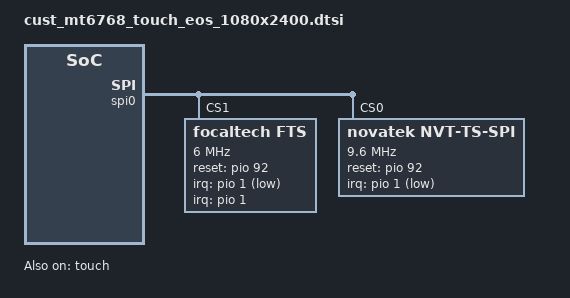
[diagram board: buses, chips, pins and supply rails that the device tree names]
/*
 * Copyright (c) 2019 MediaTek Inc.
 *
 * This program is free software; you can redistribute it and/or modify
 * it under the terms of the GNU General Public License version 2 as
 * published by the Free Software Foundation.
 *
 * This program is distributed in the hope that it will be useful,
 * but WITHOUT ANY WARRANTY; without even the implied warranty of
 * MERCHANTABILITY or FITNESS FOR A PARTICULAR PURPOSE.  See the
 * GNU General Public License for more details.
 */
/* TOUCH start */

&touch {
	tpd-resolution = <1080 2400>;
	use-tpd-button = <0>;
	tpd-key-num = <3>;
	tpd-key-local= <139 172 158 0>;
	tpd-key-dim-local = <90 883 100 40 230
				883 100 40 370 883 100 40 0 0 0 0>;
	tpd-max-touch-num = <10>;
	tpd-filter-enable = <0>;
	tpd-filter-pixel-density = <168>;
	tpd-filter-custom-prameters = <0 0 0 0 0 0 0 0 0 0 0 0>;
	tpd-filter-custom-speed = <0 0 0>;
	pinctrl-names = "default", "state_eint_as_int",
		"state_eint_output0", "state_eint_output1",
		"state_rst_output0", "state_rst_output1";
	pinctrl-0 = <&ctp_pins_default>;
	pinctrl-1 = <&ctp_pins_eint_as_int>;
	pinctrl-2 = <&ctp_pins_eint_output0>;
	pinctrl-3 = <&ctp_pins_eint_output1>;
	pinctrl-4 = <&ctp_pins_rst_output0>;
	pinctrl-5 = <&ctp_pins_rst_output1>;
	status = "okay";
};
&pio {
	ctp_pins_default: eint0default {
	};
	ctp_ts_pins_default: eint1default {
	};
	ctp_pins_eint_as_int: eint@0 {
		pins_cmd_dat {
			pinmux = <PINMUX_GPIO1__FUNC_GPIO1>;
			slew-rate = <0>;
			bias-disable;
		};
	};
	ctp_pins_eint_output0: eintoutput0 {
		pins_cmd_dat {
			pinmux = <PINMUX_GPIO1__FUNC_GPIO1>;
			slew-rate = <1>;
			output-low;
		};
	};
	ctp_pins_eint_output1: eintoutput1 {
		pins_cmd_dat {
			pinmux = <PINMUX_GPIO1__FUNC_GPIO1>;
			slew-rate = <1>;
			output-high;
	};
	};
	ctp_pins_rst_output0: rstoutput0 {
		pins_cmd_dat {
				pinmux = <PINMUX_GPIO92__FUNC_GPIO92>;
				slew-rate = <1>;
				output-low;
			};
	};
	ctp_pins_rst_output1: rstoutput1 {
		pins_cmd_dat {
				pinmux = <PINMUX_GPIO92__FUNC_GPIO92>;
				slew-rate = <1>;
				output-high;
		};
	};

};

&spi0 {
/*K19A coad for HQ-148596 by caogaojie at 2021/9/27 start*/
	focaltech@0 {
		compatible = "focaltech,fts";
		reg = <1>;
		status = "ok";
		spi-max-frequency = <6000000>;
		interrupt-parent = <&pio>;
		interrupts = <1 0x2>;
		focaltech,reset-gpio = <&pio 92 0x00>;
		focaltech,irq-gpio = <&pio 1 0x2001>;
		focaltech,max-touch-number = <10>;
		focaltech,display-coords =  <0 0 1080 2400>;
	};
	novatek@0 {
		compatible = "novatek,NVT-ts-spi";
/*K19A coad for HQ-148596 by caogaojie at 2021/9/27 end*/
		reg = <0>; //Same as CS ID
		status = "ok";

		spi-max-frequency = <9600000>;	//4800000,9600000,15000000,19200000
		novatek,reset-gpio = <&pio 92 0x00>;
		novatek,irq-gpio = <&pio 1 0x2001>;

		/* 525 */
		//novatek,swrst-n8-addr = <0x01F01A>;

		/* 672A, 525B, 675, 526, 672C */
		novatek,swrst-n8-addr = <0x03F0FE>;
		novatek,spi-rd-fast-addr = <0x03F310>;

		/* MP */
		novatek,mp-support-dt;

		/*for Xiaomi K19A 672C TM6.497" Module*/
		novatek-mp-criteria-5955@0 {
			#address-cells = <1>;
			#size-cells = <0>;
			compatible = "novatek-mp-criteria-5955";

			/* MP Config */
			IC_X_CFG_SIZE = <18>;
			IC_Y_CFG_SIZE = <36>;
			IC_KEY_CFG_SIZE = <4>;
			X_Channel = <18>;
			Y_Channel = <36>;
			AIN_X = <0 1 2 3 4 5 6 7 8 9 10 11 12 13 14 15 16 17>;
			AIN_Y = <0 1 2 3 4 5 6 7 8 9 10 11 12 13 14 15 16 17 18 19 20 21 22 23 24 25 26 27 28 29 30 31 32 33 34 35>;
			//AIN_X = <0 1 2 3 4 5 6 7 8 9 10 11 12 13 14 15 16 17 18 19 20 21 22 23 24 25 26 27 28 29 30 31>;
			//AIN_Y = <0 1 2 3 4 5 6 7 8 9 10 11 12 13 14 15 16 17 18 19 20 21 22 23 24 25 26 27 28 29 30 31 32 33 34 35 36 37 38 39 40 41 42 43 44 45 46 47 48 49>;
			AIN_KEY = <0 1 2 0xFF>;

			/* Huaqin modify for HQ-152284 by jaingyue at 2021/09/17 start */

			/* MP Criteria */
			PS_Config_Lmt_Short_Rawdata_P = <
				14008	14008	14008	14008	14008	14008	14008	14008	14008	14008	14008	14008	14008	14008	14008	14008	14008	14008
				14008	14008	14008	14008	14008	14008	14008	14008	14008	14008	14008	14008	14008	14008	14008	14008	14008	14008
				14008	14008	14008	14008	14008	14008	14008	14008	14008	14008	14008	14008	14008	14008	14008	14008	14008	14008
				14008	14008	14008	14008	14008	14008	14008	14008	14008	14008	14008	14008	14008	14008	14008	14008	14008	14008
				14008	14008	14008	14008	14008	14008	14008	14008	14008	14008	14008	14008	14008	14008	14008	14008	14008	14008
				14008	14008	14008	14008	14008	14008	14008	14008	14008	14008	14008	14008	14008	14008	14008	14008	14008	14008
				14008	14008	14008	14008	14008	14008	14008	14008	14008	14008	14008	14008	14008	14008	14008	14008	14008	14008
				14008	14008	14008	14008	14008	14008	14008	14008	14008	14008	14008	14008	14008	14008	14008	14008	14008	14008
				14008	14008	14008	14008	14008	14008	14008	14008	14008	14008	14008	14008	14008	14008	14008	14008	14008	14008
				14008	14008	14008	14008	14008	14008	14008	14008	14008	14008	14008	14008	14008	14008	14008	14008	14008	14008
				14008	14008	14008	14008	14008	14008	14008	14008	14008	14008	14008	14008	14008	14008	14008	14008	14008	14008
				14008	14008	14008	14008	14008	14008	14008	14008	14008	14008	14008	14008	14008	14008	14008	14008	14008	14008
				14008	14008	14008	14008	14008	14008	14008	14008	14008	14008	14008	14008	14008	14008	14008	14008	14008	14008
				14008	14008	14008	14008	14008	14008	14008	14008	14008	14008	14008	14008	14008	14008	14008	14008	14008	14008
				14008	14008	14008	14008	14008	14008	14008	14008	14008	14008	14008	14008	14008	14008	14008	14008	14008	14008
				14008	14008	14008	14008	14008	14008	14008	14008	14008	14008	14008	14008	14008	14008	14008	14008	14008	14008
				14008	14008	14008	14008	14008	14008	14008	14008	14008	14008	14008	14008	14008	14008	14008	14008	14008	14008
				14008	14008	14008	14008	14008	14008	14008	14008	14008	14008	14008	14008	14008	14008	14008	14008	14008	14008
				14008	14008	14008	14008	14008	14008	14008	14008	14008	14008	14008	14008	14008	14008	14008	14008	14008	14008
				14008	14008	14008	14008	14008	14008	14008	14008	14008	14008	14008	14008	14008	14008	14008	14008	14008	14008
				14008	14008	14008	14008	14008	14008	14008	14008	14008	14008	14008	14008	14008	14008	14008	14008	14008	14008
				14008	14008	14008	14008	14008	14008	14008	14008	14008	14008	14008	14008	14008	14008	14008	14008	14008	14008
				14008	14008	14008	14008	14008	14008	14008	14008	14008	14008	14008	14008	14008	14008	14008	14008	14008	14008
				14008	14008	14008	14008	14008	14008	14008	14008	14008	14008	14008	14008	14008	14008	14008	14008	14008	14008
				14008	14008	14008	14008	14008	14008	14008	14008	14008	14008	14008	14008	14008	14008	14008	14008	14008	14008
				14008	14008	14008	14008	14008	14008	14008	14008	14008	14008	14008	14008	14008	14008	14008	14008	14008	14008
				14008	14008	14008	14008	14008	14008	14008	14008	14008	14008	14008	14008	14008	14008	14008	14008	14008	14008
				14008	14008	14008	14008	14008	14008	14008	14008	14008	14008	14008	14008	14008	14008	14008	14008	14008	14008
				14008	14008	14008	14008	14008	14008	14008	14008	14008	14008	14008	14008	14008	14008	14008	14008	14008	14008
				14008	14008	14008	14008	14008	14008	14008	14008	14008	14008	14008	14008	14008	14008	14008	14008	14008	14008
				14008	14008	14008	14008	14008	14008	14008	14008	14008	14008	14008	14008	14008	14008	14008	14008	14008	14008
				14008	14008	14008	14008	14008	14008	14008	14008	14008	14008	14008	14008	14008	14008	14008	14008	14008	14008
				14008	14008	14008	14008	14008	14008	14008	14008	14008	14008	14008	14008	14008	14008	14008	14008	14008	14008
				14008	14008	14008	14008	14008	14008	14008	14008	14008	14008	14008	14008	14008	14008	14008	14008	14008	14008
				14008	14008	14008	14008	14008	14008	14008	14008	14008	14008	14008	14008	14008	14008	14008	14008	14008	14008
				14008	14008	14008	14008	14008	14008	14008	14008	14008	14008	14008	14008	14008	14008	14008	14008	14008	14008
				14008 14008 14008>;

			PS_Config_Lmt_Short_Rawdata_N = <
				10100	10100	10100	10100	10100	10100	10100	10100	10100	10100	10100	10100	10100	10100	10100	10100	10100	10100
				10100	10100	10100	10100	10100	10100	10100	10100	10100	10100	10100	10100	10100	10100	10100	10100	10100	10100
				10100	10100	10100	10100	10100	10100	10100	10100	10100	10100	10100	10100	10100	10100	10100	10100	10100	10100
				10100	10100	10100	10100	10100	10100	10100	10100	10100	10100	10100	10100	10100	10100	10100	10100	10100	10100
				10100	10100	10100	10100	10100	10100	10100	10100	10100	10100	10100	10100	10100	10100	10100	10100	10100	10100
				10100	10100	10100	10100	10100	10100	10100	10100	10100	10100	10100	10100	10100	10100	10100	10100	10100	10100
				10100	10100	10100	10100	10100	10100	10100	10100	10100	10100	10100	10100	10100	10100	10100	10100	10100	10100
				10100	10100	10100	10100	10100	10100	10100	10100	10100	10100	10100	10100	10100	10100	10100	10100	10100	10100
				10100	10100	10100	10100	10100	10100	10100	10100	10100	10100	10100	10100	10100	10100	10100	10100	10100	10100
				10100	10100	10100	10100	10100	10100	10100	10100	10100	10100	10100	10100	10100	10100	10100	10100	10100	10100
				10100	10100	10100	10100	10100	10100	10100	10100	10100	10100	10100	10100	10100	10100	10100	10100	10100	10100
				10100	10100	10100	10100	10100	10100	10100	10100	10100	10100	10100	10100	10100	10100	10100	10100	10100	10100
				10100	10100	10100	10100	10100	10100	10100	10100	10100	10100	10100	10100	10100	10100	10100	10100	10100	10100
				10100	10100	10100	10100	10100	10100	10100	10100	10100	10100	10100	10100	10100	10100	10100	10100	10100	10100
				10100	10100	10100	10100	10100	10100	10100	10100	10100	10100	10100	10100	10100	10100	10100	10100	10100	10100
				10100	10100	10100	10100	10100	10100	10100	10100	10100	10100	10100	10100	10100	10100	10100	10100	10100	10100
				10100	10100	10100	10100	10100	10100	10100	10100	10100	10100	10100	10100	10100	10100	10100	10100	10100	10100
				10100	10100	10100	10100	10100	10100	10100	10100	10100	10100	10100	10100	10100	10100	10100	10100	10100	10100
				10100	10100	10100	10100	10100	10100	10100	10100	10100	10100	10100	10100	10100	10100	10100	10100	10100	10100
				10100	10100	10100	10100	10100	10100	10100	10100	10100	10100	10100	10100	10100	10100	10100	10100	10100	10100
				10100	10100	10100	10100	10100	10100	10100	10100	10100	10100	10100	10100	10100	10100	10100	10100	10100	10100
				10100	10100	10100	10100	10100	10100	10100	10100	10100	10100	10100	10100	10100	10100	10100	10100	10100	10100
				10100	10100	10100	10100	10100	10100	10100	10100	10100	10100	10100	10100	10100	10100	10100	10100	10100	10100
				10100	10100	10100	10100	10100	10100	10100	10100	10100	10100	10100	10100	10100	10100	10100	10100	10100	10100
				10100	10100	10100	10100	10100	10100	10100	10100	10100	10100	10100	10100	10100	10100	10100	10100	10100	10100
				10100	10100	10100	10100	10100	10100	10100	10100	10100	10100	10100	10100	10100	10100	10100	10100	10100	10100
				10100	10100	10100	10100	10100	10100	10100	10100	10100	10100	10100	10100	10100	10100	10100	10100	10100	10100
				10100	10100	10100	10100	10100	10100	10100	10100	10100	10100	10100	10100	10100	10100	10100	10100	10100	10100
				10100	10100	10100	10100	10100	10100	10100	10100	10100	10100	10100	10100	10100	10100	10100	10100	10100	10100
				10100	10100	10100	10100	10100	10100	10100	10100	10100	10100	10100	10100	10100	10100	10100	10100	10100	10100
				10100	10100	10100	10100	10100	10100	10100	10100	10100	10100	10100	10100	10100	10100	10100	10100	10100	10100
				10100	10100	10100	10100	10100	10100	10100	10100	10100	10100	10100	10100	10100	10100	10100	10100	10100	10100
				10100	10100	10100	10100	10100	10100	10100	10100	10100	10100	10100	10100	10100	10100	10100	10100	10100	10100
				10100	10100	10100	10100	10100	10100	10100	10100	10100	10100	10100	10100	10100	10100	10100	10100	10100	10100
				10100	10100	10100	10100	10100	10100	10100	10100	10100	10100	10100	10100	10100	10100	10100	10100	10100	10100
				10100	10100	10100	10100	10100	10100	10100	10100	10100	10100	10100	10100	10100	10100	10100	10100	10100	10100
				10000 10000 10000>;

			PS_Config_Lmt_Open_Rawdata_P = <
				2959	2973	3073	3136	3161	3193	3234	3264	3259	3329	3305	3267	3207	3171	3127	3053	2933	2851
				2913	3001	3071	3136	3165	3192	3229	3263	3291	3347	3313	3273	3217	3182	3145	3073	2982	2895
				2994	3054	3119	3192	3224	3243	3284	3319	3354	3389	3368	3312	3249	3206	3171	3081	2996	2896
				3011	3042	3120	3215	3259	3290	3346	3392	3434	3462	3393	3347	3277	3232	3183	3088	3001	2982
				3046	3070	3144	3239	3276	3297	3332	3375	3473	3501	3421	3371	3285	3242	3182	3078	2987	2986
				3040	3077	3151	3249	3302	3337	3382	3437	3523	3501	3434	3397	3319	3280	3220	3117	3029	3050
				3084	3109	3186	3277	3325	3350	3389	3432	3546	3595	3525	3473	3393	3332	3253	3143	3033	3038
				3077	3119	3213	3306	3372	3406	3446	3469	3593	3591	3519	3469	3397	3343	3262	3158	3031	3085
				3147	3179	3266	3361	3427	3446	3487	3544	3651	3649	3584	3525	3451	3393	3305	3192	3108	3103
				3150	3197	3283	3383	3459	3484	3530	3593	3682	3683	3627	3570	3497	3446	3354	3235	3152	3173
				3201	3243	3322	3423	3495	3518	3519	3630	3729	3696	3627	3579	3497	3444	3333	3192	3136	3137
				3211	3271	3357	3463	3542	3570	3623	3684	3756	3696	3637	3593	3522	3480	3378	3276	3189	3208
				3257	3306	3397	3493	3579	3609	3666	3726	3815	3753	3701	3652	3584	3521	3409	3305	3201	3197
				3248	3312	3411	3507	3602	3637	3704	3761	3830	3773	3719	3673	3606	3553	3430	3337	3245	3264
				3313	3369	3452	3544	3638	3638	3733	3782	3865	3844	3785	3725	3648	3596	3446	3368	3281	3263
				3285	3367	3459	3556	3658	3707	3774	3831	3892	3845	3795	3742	3676	3620	3509	3395	3309	3322
				3334	3409	3480	3575	3670	3726	3788	3838	3903	3882	3824	3771	3698	3644	3529	3413	3313	3312
				3329	3414	3490	3591	3686	3768	3847	3907	3952	3865	3808	3756	3690	3620	3530	3417	3329	3351
				3399	3325	3358	3414	3434	3507	3570	3627	3683	3722	3690	3647	3567	3502	3486	3442	3395	3367
				3369	3327	3361	3421	3469	3526	3595	3659	3721	3724	3675	3630	3563	3523	3490	3445	3399	3385
				3428	3372	3404	3448	3494	3540	3602	3652	3701	3747	3703	3651	3595	3557	3521	3472	3421	3389
				3388	3361	3406	3437	3519	3571	3647	3697	3752	3787	3718	3669	3586	3582	3544	3495	3444	3432
				3459	3418	3456	3511	3558	3592	3652	3691	3735	3791	3731	3683	3630	3600	3558	3504	3446	3417
				3442	3430	3466	3537	3584	3628	3700	3749	3802	3840	3767	3718	3675	3649	3612	3553	3500	3477
				3488	3453	3491	3551	3595	3631	3689	3731	3773	3859	3794	3743	3696	3662	3620	3568	3504	3472
				3453	3452	3479	3572	3626	3675	3740	3791	3847	3837	3756	3682	3666	3638	3606	3557	3498	3470
				3511	3487	3547	3602	3644	3676	3743	3781	3834	3833	3764	3725	3687	3656	3624	3564	3511	3463
				3452	3449	3525	3582	3635	3673	3745	3788	3851	3852	3766	3729	3694	3668	3634	3584	3535	3507
				3507	3476	3560	3619	3659	3691	3754	3792	3852	3859	3767	3747	3694	3665	3623	3565	3507	3453
				3462	3477	3547	3616	3661	3700	3775	3816	3879	3859	3784	3745	3698	3670	3637	3581	3522	3495
				3488	3490	3565	3626	3669	3705	3764	3801	3852	3865	3805	3766	3729	3693	3658	3606	3532	3490
				3476	3500	3586	3641	3689	3736	3798	3840	3907	3883	3810	3774	3739	3711	3680	3635	3560	3549
				3491	3519	3610	3658	3704	3738	3799	3833	3892	3847	3805	3766	3729	3698	3672	3623	3551	3522
				3437	3551	3662	3725	3780	3829	3907	3952	4018	3976	3911	3868	3823	3789	3756	3698	3609	3518
				3341	3605	3710	3767	3813	3845	3906	3948	4009	4013	3957	3925	3865	3833	3788	3724	3610	3372
				3152	3546	3703	3778	3827	3873	3949	4006	4075	3992	3935	3903	3847	3813	3780	3725	3584	3253
				5120 5120 5120>;

			PS_Config_Lmt_Open_Rawdata_N = <
				1268	1274	1317	1344	1354	1368	1386	1399	1396	1426	1416	1400	1374	1359	1340	1308	1257	1222
				1248	1286	1316	1344	1356	1368	1384	1398	1410	1434	1420	1402	1378	1363	1348	1317	1278	1240
				1283	1309	1336	1368	1381	1390	1407	1422	1437	1452	1443	1419	1392	1374	1359	1320	1284	1241
				1290	1303	1337	1378	1396	1410	1434	1453	1471	1483	1454	1434	1404	1385	1364	1323	1286	1278
				1305	1315	1347	1388	1404	1413	1428	1446	1488	1500	1466	1444	1408	1389	1363	1319	1280	1279
				1303	1318	1350	1392	1415	1430	1449	1473	1510	1500	1471	1456	1422	1405	1380	1336	1298	1307
				1321	1332	1365	1404	1425	1435	1452	1471	1519	1540	1510	1488	1454	1428	1394	1347	1300	1302
				1318	1336	1377	1417	1445	1459	1477	1486	1540	1539	1508	1486	1456	1432	1398	1353	1299	1322
				1348	1362	1399	1440	1468	1477	1494	1519	1564	1564	1536	1510	1479	1454	1416	1368	1332	1330
				1350	1370	1407	1450	1482	1493	1513	1540	1578	1578	1554	1530	1498	1477	1437	1386	1351	1360
				1372	1390	1423	1467	1498	1507	1508	1555	1598	1584	1554	1534	1498	1476	1428	1368	1344	1344
				1376	1402	1438	1484	1518	1530	1552	1579	1609	1584	1558	1540	1509	1491	1447	1404	1366	1375
				1396	1417	1456	1497	1534	1546	1571	1597	1635	1608	1586	1565	1536	1509	1461	1416	1372	1370
				1392	1419	1462	1503	1543	1558	1587	1612	1641	1617	1594	1574	1545	1522	1470	1430	1390	1399
				1420	1444	1479	1519	1559	1559	1600	1621	1656	1647	1622	1596	1563	1541	1477	1443	1406	1398
				1408	1443	1482	1524	1567	1588	1617	1642	1668	1648	1626	1603	1575	1551	1504	1455	1418	1423
				1429	1461	1491	1532	1573	1597	1623	1645	1672	1663	1639	1616	1585	1561	1512	1462	1420	1419
				1426	1463	1495	1539	1579	1615	1648	1674	1693	1656	1632	1609	1581	1551	1513	1464	1426	1436
				1456	1425	1439	1463	1471	1503	1530	1554	1578	1595	1581	1563	1528	1501	1494	1475	1455	1443
				1444	1426	1440	1466	1486	1511	1540	1568	1594	1596	1575	1555	1527	1510	1495	1476	1456	1450
				1469	1445	1459	1477	1497	1517	1543	1565	1586	1606	1587	1564	1540	1524	1509	1488	1466	1452
				1452	1440	1459	1473	1508	1530	1563	1584	1608	1623	1593	1572	1537	1535	1519	1498	1476	1471
				1482	1465	1481	1504	1525	1539	1565	1582	1600	1624	1599	1578	1555	1543	1525	1501	1477	1464
				1475	1470	1485	1516	1536	1555	1585	1606	1629	1645	1614	1593	1575	1564	1548	1522	1500	1490
				1495	1480	1496	1522	1540	1556	1581	1599	1617	1654	1626	1604	1584	1569	1551	1529	1501	1488
				1480	1479	1491	1531	1554	1575	1603	1624	1648	1644	1609	1578	1571	1559	1545	1524	1499	1487
				1504	1494	1520	1543	1561	1575	1604	1620	1643	1642	1613	1596	1580	1567	1553	1527	1504	1484
				1479	1478	1510	1535	1558	1574	1605	1623	1650	1651	1614	1598	1583	1572	1557	1536	1515	1503
				1503	1489	1525	1551	1568	1582	1609	1625	1651	1654	1614	1606	1583	1570	1552	1528	1503	1480
				1483	1490	1520	1549	1569	1585	1618	1635	1662	1654	1621	1605	1585	1573	1558	1534	1509	1498
				1495	1495	1528	1554	1572	1588	1613	1629	1651	1656	1630	1614	1598	1582	1567	1545	1513	1495
				1489	1500	1537	1560	1581	1601	1627	1645	1674	1664	1633	1617	1602	1590	1577	1558	1525	1521
				1496	1508	1547	1567	1587	1602	1628	1642	1668	1648	1630	1614	1598	1585	1573	1552	1522	1509
				1473	1522	1569	1596	1620	1641	1674	1693	1722	1704	1676	1657	1638	1624	1609	1585	1546	1507
				1432	1545	1590	1614	1634	1648	1674	1692	1718	1720	1696	1682	1656	1642	1623	1596	1547	1445
				1351	1519	1587	1619	1640	1660	1692	1717	1746	1711	1686	1672	1648	1634	1620	1596	1536	1394
				(-511) (-511) (-511)>;

			PS_Config_Lmt_FW_Rawdata_P = <
				1118	1111	1118	1113	1117	1113	1111	1122	1115	1138	1115	1113	1108	1092	1101	1093	1106	1101
				1103	1118	1127	1117	1121	1115	1113	1125	1106	1118	1110	1131	1129	1131	1131	1125	1114	1093
				1117	1107	1110	1110	1113	1106	1107	1117	1121	1111	1107	1113	1115	1114	1117	1108	1134	1110
				1099	1125	1148	1145	1125	1139	1139	1100	1107	1120	1115	1113	1111	1111	1106	1117	1115	1117
				1122	1114	1117	1121	1111	1122	1121	1113	1101	1113	1115	1125	1124	1115	1117	1118	1122	1111
				1103	1117	1125	1121	1128	1122	1134	1090	1097	1108	1100	1107	1108	1113	1113	1107	1110	1113
				1103	1108	1115	1114	1122	1122	1117	1115	1115	1127	1115	1114	1111	1114	1117	1117	1125	1118
				1107	1125	1132	1128	1113	1131	1118	1106	1110	1118	1099	1093	1094	1092	1100	1128	1122	1120
				1108	1108	1107	1120	1107	1129	1125	1134	1120	1107	1094	1096	1111	1120	1122	1114	1122	1103
				1129	1108	1115	1122	1118	1132	1132	1103	1108	1115	1100	1120	1128	1129	1125	1129	1122	1097
				1108	1094	1100	1089	1086	1100	1093	1113	1111	1120	1108	1114	1121	1118	1115	1120	1120	1113
				1108	1127	1136	1131	1135	1099	1115	1129	1139	1108	1117	1113	1125	1132	1128	1127	1125	1117
				1122	1122	1125	1127	1120	1120	1122	1093	1093	1096	1143	1136	1122	1122	1120	1113	1111	1122
				1124	1121	1132	1122	1127	1114	1124	1118	1125	1136	1101	1099	1117	1125	1111	1132	1129	1127
				1120	1106	1107	1113	1101	1125	1128	1127	1111	1108	1131	1124	1122	1127	1127	1115	1117	1103
				1120	1096	1099	1110	1107	1120	1120	1110	1128	1106	1124	1125	1125	1129	1117	1132	1134	1121
				1124	1121	1129	1131	1124	1115	1118	1107	1108	1110	1106	1111	1111	1101	1104	1128	1120	1125
				1113	1121	1125	1122	1118	1103	1106	1125	1104	1117	1104	1104	1108	1111	1135	1136	1141	1131
				1131	1136	1117	1118	1118	1131	1132	1113	1122	1117	1111	1120	1111	1113	1114	1125	1127	1106
				1111	1120	1124	1118	1117	1134	1134	1118	1106	1125	1117	1128	1124	1096	1103	1097	1101	1132
				1121	1114	1115	1108	1117	1110	1110	1104	1115	1114	1106	1117	1115	1128	1111	1113	1113	1107
				1107	1096	1097	1100	1110	1113	1121	1115	1118	1121	1118	1117	1113	1128	1121	1114	1124	1118
				1113	1110	1114	1115	1108	1115	1120	1118	1114	1117	1115	1115	1120	1107	1108	1113	1115	1125
				1122	1113	1104	1107	1107	1110	1120	1117	1127	1145	1117	1094	1092	1121	1104	1117	1117	1111
				1104	1117	1115	1122	1117	1108	1135	1138	1134	1117	1118	1115	1117	1128	1124	1128	1129	1114
				1115	1114	1113	1113	1115	1120	1108	1108	1115	1100	1094	1129	1136	1121	1124	1127	1132	1096
				1122	1106	1107	1104	1103	1094	1114	1115	1128	1139	1117	1120	1114	1103	1101	1103	1096	1122
				1124	1115	1124	1115	1127	1121	1131	1121	1103	1110	1104	1115	1120	1118	1121	1120	1113	1106
				1129	1101	1104	1111	1101	1113	1106	1103	1128	1107	1124	1125	1121	1127	1124	1124	1124	1113
				1134	1120	1096	1127	1096	1128	1092	1092	1120	1120	1129	1108	1115	1111	1113	1115	1113	1111
				1127	1103	1117	1106	1108	1110	1113	1110	1107	1120	1111	1108	1104	1107	1111	1108	1106	1117
				1120	1115	1117	1121	1121	1117	1117	1107	1114	1113	1111	1090	1104	1101	1108	1099	1120	1125
				1131	1097	1100	1090	1110	1092	1106	1090	1124	1106	1121	1107	1115	1122	1122	1108	1122	1115
				1100	1121	1138	1124	1131	1125	1129	1132	1115	1125	1111	1135	1125	1127	1124	1135	1114	1118
				1129	1138	1120	1142	1117	1141	1110	1136	1117	1124	1110	1121	1108	1110	1110	1120	1100	1121
				1124	1117	1127	1124	1122	1135	1094	1113	1120	1132	1111	1110	1118	1103	1125	1121	1132	1125
				2560 2560 2560>;

			PS_Config_Lmt_FW_Rawdata_N = <
				479	476	479	477	478	477	476	481	478	487	478	477	475	468	472	468	474	472
				472	479	483	478	480	478	477	482	474	479	475	484	484	484	484	482	477	468
				478	474	475	475	477	474	474	478	480	476	474	477	478	477	478	475	486	475
				471	482	492	490	482	488	488	471	474	480	478	477	476	476	474	478	478	478
				481	477	478	480	476	481	480	477	472	477	478	482	481	478	478	479	481	476
				472	478	482	480	483	481	486	467	470	475	471	474	475	477	477	474	475	477
				472	475	478	477	481	481	478	478	478	483	478	477	476	477	478	478	482	479
				474	482	485	483	477	484	479	474	475	479	471	468	469	468	471	483	481	480
				475	475	474	480	474	484	482	486	480	474	469	469	476	480	481	477	481	472
				484	475	478	481	479	485	485	472	475	478	471	480	483	484	482	484	481	470
				475	469	471	466	465	471	468	477	476	480	475	477	480	479	478	480	480	477
				475	483	487	484	486	471	478	484	488	475	478	477	482	485	483	483	482	478
				481	481	482	483	480	480	481	468	468	469	490	487	481	481	480	477	476	481
				481	480	485	481	483	477	481	479	482	487	472	471	478	482	476	485	484	483
				480	474	474	477	472	482	483	483	476	475	484	481	481	483	483	478	478	472
				480	469	471	475	474	480	480	475	483	474	481	482	482	484	478	485	486	480
				481	480	484	484	481	478	479	474	475	475	474	476	476	472	473	483	480	482
				477	480	482	481	479	472	474	482	473	478	473	473	475	476	486	487	489	484
				484	487	478	479	479	484	485	477	481	478	476	480	476	477	477	482	483	474
				476	480	481	479	478	486	486	479	474	482	478	483	481	469	472	470	472	485
				480	477	478	475	478	475	475	473	478	477	474	478	478	483	476	477	477	474
				474	469	470	471	475	477	480	478	479	480	479	478	477	483	480	477	481	479
				477	475	477	478	475	478	480	479	477	478	478	478	480	474	475	477	478	482
				481	477	473	474	474	475	480	478	483	490	478	469	468	480	473	478	478	476
				473	478	478	481	478	475	486	487	486	478	479	478	478	483	481	483	484	477
				478	477	477	477	478	480	475	475	478	471	469	484	487	480	481	483	485	469
				481	474	474	473	472	469	477	478	483	488	478	480	477	472	472	472	469	481
				481	478	481	478	483	480	484	480	472	475	473	478	480	479	480	480	477	474
				484	472	473	476	472	477	474	472	483	474	481	482	480	483	481	481	481	477
				486	480	469	483	469	483	468	468	480	480	484	475	478	476	477	478	477	476
				483	472	478	474	475	475	477	475	474	480	476	475	473	474	476	475	474	478
				480	478	478	480	480	478	478	474	477	477	476	467	473	472	475	471	480	482
				484	470	471	467	475	468	474	467	481	474	480	474	478	481	481	475	481	478
				471	480	487	481	484	482	484	485	478	482	476	486	482	483	481	486	477	479
				484	487	480	489	478	489	475	487	478	481	475	480	475	475	475	480	471	480
				481	478	483	481	481	486	469	477	480	485	476	475	479	472	482	480	485	482
				240 240 240>;

			PS_Config_Lmt_FW_CC_P = <
				52	52	52	52	52	52	52	53	55	55	53	53	53	53	53	53	53	53
				52	52	52	52	52	52	52	52	55	55	52	52	52	52	52	52	52	53
				52	52	52	52	52	52	52	52	55	53	52	52	52	52	52	52	52	52
				53	52	52	52	52	52	52	53	55	53	53	52	52	52	52	52	52	53
				52	52	52	52	52	52	52	52	53	53	52	52	52	52	52	52	52	53
				53	52	52	52	52	53	52	53	55	55	53	52	52	52	52	52	52	53
				53	52	52	52	52	52	52	52	53	53	53	52	52	52	52	52	52	53
				53	52	53	53	53	53	53	53	55	55	52	52	52	52	52	52	52	53
				52	52	52	52	52	52	52	52	53	55	53	53	53	52	52	52	52	53
				53	52	52	52	52	53	52	53	55	55	53	53	53	53	53	52	52	53
				52	52	52	52	52	52	52	53	53	55	53	53	52	52	52	52	52	53
				53	52	52	53	53	53	53	53	55	55	53	53	52	52	52	52	52	53
				53	52	52	52	52	53	52	53	55	53	53	53	53	52	53	52	52	53
				53	52	52	53	53	53	53	53	55	53	53	53	52	52	52	52	52	53
				52	52	52	52	52	52	52	53	55	53	53	53	53	53	53	53	53	53
				53	53	53	53	53	53	53	55	56	53	53	53	53	53	53	52	52	53
				53	52	52	52	52	53	53	53	55	53	53	53	53	53	52	52	52	53
				53	52	53	53	53	53	53	53	56	53	52	53	53	52	52	52	52	53
				53	52	52	52	52	52	52	52	52	56	53	53	53	53	53	52	52	53
				53	52	52	52	52	53	53	53	53	56	53	53	53	53	53	53	52	53
				53	52	52	52	52	52	52	52	52	55	53	53	53	52	52	52	52	53
				53	53	53	53	53	53	53	53	53	56	53	53	53	52	53	52	52	53
				53	52	52	52	52	52	53	53	53	55	53	53	53	52	53	52	52	53
				53	53	53	53	53	53	53	53	53	55	53	53	53	53	53	53	53	53
				53	52	52	52	52	52	53	53	55	55	53	53	53	53	53	53	53	53
				53	53	53	53	53	53	53	53	55	56	53	53	53	53	53	53	53	53
				53	52	53	53	53	53	53	53	55	55	53	53	53	53	53	53	53	53
				55	53	53	53	53	53	53	53	56	55	53	53	53	53	53	53	53	53
				53	52	53	52	53	52	53	53	53	55	53	53	53	53	53	53	53	53
				53	53	53	53	53	53	53	53	55	55	53	53	53	53	53	53	53	53
				53	53	53	52	53	52	53	53	55	55	53	53	53	53	53	53	53	55
				55	53	53	53	53	53	53	53	56	55	53	53	53	53	53	53	53	55
				53	53	53	53	53	53	53	53	55	55	53	53	53	53	53	53	53	55
				55	53	53	53	53	53	53	53	56	56	53	53	53	53	53	53	53	53
				52	52	53	52	52	52	53	52	55	55	53	53	53	53	53	53	53	53
				53	53	53	53	53	53	53	55	56	56	55	53	53	53	53	53	53	53
				314 314 314>;

			PS_Config_Lmt_FW_CC_N = <
				23	23	23	23	23	23	23	24	24	24	24	24	24	24	24	24	24	24
				23	23	23	23	23	23	23	23	24	24	23	23	23	23	23	23	23	24
				23	23	23	23	23	23	23	23	24	24	23	23	23	23	23	23	23	23
				24	23	23	23	23	23	23	24	24	24	24	23	23	23	23	23	23	24
				23	23	23	23	23	23	23	23	24	24	23	23	23	23	23	23	23	24
				24	23	23	23	23	24	23	24	24	24	24	23	23	23	23	23	23	24
				24	23	23	23	23	23	23	23	24	24	24	23	23	23	23	23	23	24
				24	23	24	24	24	24	24	24	24	24	23	23	23	23	23	23	23	24
				23	23	23	23	23	23	23	23	24	24	24	24	24	23	23	23	23	24
				24	23	23	23	23	24	23	24	24	24	24	24	24	24	24	23	23	24
				23	23	23	23	23	23	23	24	24	24	24	24	23	23	23	23	23	24
				24	23	23	24	24	24	24	24	24	24	24	24	23	23	23	23	23	24
				24	23	23	23	23	24	23	24	24	24	24	24	24	23	24	23	23	24
				24	23	23	24	24	24	24	24	24	24	24	24	23	23	23	23	23	24
				23	23	23	23	23	23	23	24	24	24	24	24	24	24	24	24	24	24
				24	24	24	24	24	24	24	24	25	24	24	24	24	24	24	23	23	24
				24	23	23	23	23	24	24	24	24	24	24	24	24	24	23	23	23	24
				24	23	24	24	24	24	24	24	25	24	23	24	24	23	23	23	23	24
				24	23	23	23	23	23	23	23	23	25	24	24	24	24	24	23	23	24
				24	23	23	23	23	24	24	24	24	25	24	24	24	24	24	24	23	24
				24	23	23	23	23	23	23	23	23	24	24	24	24	23	23	23	23	24
				24	24	24	24	24	24	24	24	24	25	24	24	24	23	24	23	23	24
				24	23	23	23	23	23	24	24	24	24	24	24	24	23	24	23	23	24
				24	24	24	24	24	24	24	24	24	24	24	24	24	24	24	24	24	24
				24	23	23	23	23	23	24	24	24	24	24	24	24	24	24	24	24	24
				24	24	24	24	24	24	24	24	24	25	24	24	24	24	24	24	24	24
				24	23	24	24	24	24	24	24	24	24	24	24	24	24	24	24	24	24
				24	24	24	24	24	24	24	24	25	24	24	24	24	24	24	24	24	24
				24	23	24	23	24	23	24	24	24	24	24	24	24	24	24	24	24	24
				24	24	24	24	24	24	24	24	24	24	24	24	24	24	24	24	24	24
				24	24	24	23	24	23	24	24	24	24	24	24	24	24	24	24	24	24
				24	24	24	24	24	24	24	24	25	24	24	24	24	24	24	24	24	24
				24	24	24	24	24	24	24	24	24	24	24	24	24	24	24	24	24	24
				24	24	24	24	24	24	24	24	25	25	24	24	24	24	24	24	24	24
				23	23	24	23	23	23	24	23	24	24	24	24	24	24	24	24	24	24
				24	24	24	24	24	24	24	24	25	25	24	24	24	24	24	24	24	24
				0 0 0>;

			PS_Config_Lmt_FW_Diff_P = <
				50	50	50	50	50	50	50	50	50	50	50	50	50	50	50	50	50	50
				50	50	50	50	50	50	50	50	50	50	50	50	50	50	50	50	50	50
				50	50	50	50	50	50	50	50	50	50	50	50	50	50	50	50	50	50
				50	50	50	50	50	50	50	50	50	50	50	50	50	50	50	50	50	50
				50	50	50	50	50	50	50	50	50	50	50	50	50	50	50	50	50	50
				50	50	50	50	50	50	50	50	50	50	50	50	50	50	50	50	50	50
				50	50	50	50	50	50	50	50	50	50	50	50	50	50	50	50	50	50
				50	50	50	50	50	50	50	50	50	50	50	50	50	50	50	50	50	50
				50	50	50	50	50	50	50	50	50	50	50	50	50	50	50	50	50	50
				50	50	50	50	50	50	50	50	50	50	50	50	50	50	50	50	50	50
				50	50	50	50	50	50	50	50	50	50	50	50	50	50	50	50	50	50
				50	50	50	50	50	50	50	50	50	50	50	50	50	50	50	50	50	50
				50	50	50	50	50	50	50	50	50	50	50	50	50	50	50	50	50	50
				50	50	50	50	50	50	50	50	50	50	50	50	50	50	50	50	50	50
				50	50	50	50	50	50	50	50	50	50	50	50	50	50	50	50	50	50
				50	50	50	50	50	50	50	50	50	50	50	50	50	50	50	50	50	50
				50	50	50	50	50	50	50	50	50	50	50	50	50	50	50	50	50	50
				50	50	50	50	50	50	50	50	50	50	50	50	50	50	50	50	50	50
				50	50	50	50	50	50	50	50	50	50	50	50	50	50	50	50	50	50
				50	50	50	50	50	50	50	50	50	50	50	50	50	50	50	50	50	50
				50	50	50	50	50	50	50	50	50	50	50	50	50	50	50	50	50	50
				50	50	50	50	50	50	50	50	50	50	50	50	50	50	50	50	50	50
				50	50	50	50	50	50	50	50	50	50	50	50	50	50	50	50	50	50
				50	50	50	50	50	50	50	50	50	50	50	50	50	50	50	50	50	50
				50	50	50	50	50	50	50	50	50	50	50	50	50	50	50	50	50	50
				50	50	50	50	50	50	50	50	50	50	50	50	50	50	50	50	50	50
				50	50	50	50	50	50	50	50	50	50	50	50	50	50	50	50	50	50
				50	50	50	50	50	50	50	50	50	50	50	50	50	50	50	50	50	50
				50	50	50	50	50	50	50	50	50	50	50	50	50	50	50	50	50	50
				50	50	50	50	50	50	50	50	50	50	50	50	50	50	50	50	50	50
				50	50	50	50	50	50	50	50	50	50	50	50	50	50	50	50	50	50
				50	50	50	50	50	50	50	50	50	50	50	50	50	50	50	50	50	50
				50	50	50	50	50	50	50	50	50	50	50	50	50	50	50	50	50	50
				50	50	50	50	50	50	50	50	50	50	50	50	50	50	50	50	50	50
				50	50	50	50	50	50	50	50	50	50	50	50	50	50	50	50	50	50
				50	50	50	50	50	50	50	50	50	50	50	50	50	50	50	50	50	50
				75 75 75>;

			PS_Config_Lmt_FW_Diff_N = <
				(-50)	(-50)	(-50)	(-50)	(-50)	(-50)	(-50)	(-50)	(-50)	(-50)	(-50)	(-50)	(-50)	(-50)	(-50)	(-50)	(-50)	(-50)
				(-50)	(-50)	(-50)	(-50)	(-50)	(-50)	(-50)	(-50)	(-50)	(-50)	(-50)	(-50)	(-50)	(-50)	(-50)	(-50)	(-50)	(-50)
				(-50)	(-50)	(-50)	(-50)	(-50)	(-50)	(-50)	(-50)	(-50)	(-50)	(-50)	(-50)	(-50)	(-50)	(-50)	(-50)	(-50)	(-50)
				(-50)	(-50)	(-50)	(-50)	(-50)	(-50)	(-50)	(-50)	(-50)	(-50)	(-50)	(-50)	(-50)	(-50)	(-50)	(-50)	(-50)	(-50)
				(-50)	(-50)	(-50)	(-50)	(-50)	(-50)	(-50)	(-50)	(-50)	(-50)	(-50)	(-50)	(-50)	(-50)	(-50)	(-50)	(-50)	(-50)
				(-50)	(-50)	(-50)	(-50)	(-50)	(-50)	(-50)	(-50)	(-50)	(-50)	(-50)	(-50)	(-50)	(-50)	(-50)	(-50)	(-50)	(-50)
				(-50)	(-50)	(-50)	(-50)	(-50)	(-50)	(-50)	(-50)	(-50)	(-50)	(-50)	(-50)	(-50)	(-50)	(-50)	(-50)	(-50)	(-50)
				(-50)	(-50)	(-50)	(-50)	(-50)	(-50)	(-50)	(-50)	(-50)	(-50)	(-50)	(-50)	(-50)	(-50)	(-50)	(-50)	(-50)	(-50)
				(-50)	(-50)	(-50)	(-50)	(-50)	(-50)	(-50)	(-50)	(-50)	(-50)	(-50)	(-50)	(-50)	(-50)	(-50)	(-50)	(-50)	(-50)
				(-50)	(-50)	(-50)	(-50)	(-50)	(-50)	(-50)	(-50)	(-50)	(-50)	(-50)	(-50)	(-50)	(-50)	(-50)	(-50)	(-50)	(-50)
				(-50)	(-50)	(-50)	(-50)	(-50)	(-50)	(-50)	(-50)	(-50)	(-50)	(-50)	(-50)	(-50)	(-50)	(-50)	(-50)	(-50)	(-50)
				(-50)	(-50)	(-50)	(-50)	(-50)	(-50)	(-50)	(-50)	(-50)	(-50)	(-50)	(-50)	(-50)	(-50)	(-50)	(-50)	(-50)	(-50)
				(-50)	(-50)	(-50)	(-50)	(-50)	(-50)	(-50)	(-50)	(-50)	(-50)	(-50)	(-50)	(-50)	(-50)	(-50)	(-50)	(-50)	(-50)
				(-50)	(-50)	(-50)	(-50)	(-50)	(-50)	(-50)	(-50)	(-50)	(-50)	(-50)	(-50)	(-50)	(-50)	(-50)	(-50)	(-50)	(-50)
				(-50)	(-50)	(-50)	(-50)	(-50)	(-50)	(-50)	(-50)	(-50)	(-50)	(-50)	(-50)	(-50)	(-50)	(-50)	(-50)	(-50)	(-50)
				(-50)	(-50)	(-50)	(-50)	(-50)	(-50)	(-50)	(-50)	(-50)	(-50)	(-50)	(-50)	(-50)	(-50)	(-50)	(-50)	(-50)	(-50)
				(-50)	(-50)	(-50)	(-50)	(-50)	(-50)	(-50)	(-50)	(-50)	(-50)	(-50)	(-50)	(-50)	(-50)	(-50)	(-50)	(-50)	(-50)
				(-50)	(-50)	(-50)	(-50)	(-50)	(-50)	(-50)	(-50)	(-50)	(-50)	(-50)	(-50)	(-50)	(-50)	(-50)	(-50)	(-50)	(-50)
				(-50)	(-50)	(-50)	(-50)	(-50)	(-50)	(-50)	(-50)	(-50)	(-50)	(-50)	(-50)	(-50)	(-50)	(-50)	(-50)	(-50)	(-50)
				(-50)	(-50)	(-50)	(-50)	(-50)	(-50)	(-50)	(-50)	(-50)	(-50)	(-50)	(-50)	(-50)	(-50)	(-50)	(-50)	(-50)	(-50)
				(-50)	(-50)	(-50)	(-50)	(-50)	(-50)	(-50)	(-50)	(-50)	(-50)	(-50)	(-50)	(-50)	(-50)	(-50)	(-50)	(-50)	(-50)
				(-50)	(-50)	(-50)	(-50)	(-50)	(-50)	(-50)	(-50)	(-50)	(-50)	(-50)	(-50)	(-50)	(-50)	(-50)	(-50)	(-50)	(-50)
				(-50)	(-50)	(-50)	(-50)	(-50)	(-50)	(-50)	(-50)	(-50)	(-50)	(-50)	(-50)	(-50)	(-50)	(-50)	(-50)	(-50)	(-50)
				(-50)	(-50)	(-50)	(-50)	(-50)	(-50)	(-50)	(-50)	(-50)	(-50)	(-50)	(-50)	(-50)	(-50)	(-50)	(-50)	(-50)	(-50)
				(-50)	(-50)	(-50)	(-50)	(-50)	(-50)	(-50)	(-50)	(-50)	(-50)	(-50)	(-50)	(-50)	(-50)	(-50)	(-50)	(-50)	(-50)
				(-50)	(-50)	(-50)	(-50)	(-50)	(-50)	(-50)	(-50)	(-50)	(-50)	(-50)	(-50)	(-50)	(-50)	(-50)	(-50)	(-50)	(-50)
				(-50)	(-50)	(-50)	(-50)	(-50)	(-50)	(-50)	(-50)	(-50)	(-50)	(-50)	(-50)	(-50)	(-50)	(-50)	(-50)	(-50)	(-50)
				(-50)	(-50)	(-50)	(-50)	(-50)	(-50)	(-50)	(-50)	(-50)	(-50)	(-50)	(-50)	(-50)	(-50)	(-50)	(-50)	(-50)	(-50)
				(-50)	(-50)	(-50)	(-50)	(-50)	(-50)	(-50)	(-50)	(-50)	(-50)	(-50)	(-50)	(-50)	(-50)	(-50)	(-50)	(-50)	(-50)
				(-50)	(-50)	(-50)	(-50)	(-50)	(-50)	(-50)	(-50)	(-50)	(-50)	(-50)	(-50)	(-50)	(-50)	(-50)	(-50)	(-50)	(-50)
				(-50)	(-50)	(-50)	(-50)	(-50)	(-50)	(-50)	(-50)	(-50)	(-50)	(-50)	(-50)	(-50)	(-50)	(-50)	(-50)	(-50)	(-50)
				(-50)	(-50)	(-50)	(-50)	(-50)	(-50)	(-50)	(-50)	(-50)	(-50)	(-50)	(-50)	(-50)	(-50)	(-50)	(-50)	(-50)	(-50)
				(-50)	(-50)	(-50)	(-50)	(-50)	(-50)	(-50)	(-50)	(-50)	(-50)	(-50)	(-50)	(-50)	(-50)	(-50)	(-50)	(-50)	(-50)
				(-50)	(-50)	(-50)	(-50)	(-50)	(-50)	(-50)	(-50)	(-50)	(-50)	(-50)	(-50)	(-50)	(-50)	(-50)	(-50)	(-50)	(-50)
				(-50)	(-50)	(-50)	(-50)	(-50)	(-50)	(-50)	(-50)	(-50)	(-50)	(-50)	(-50)	(-50)	(-50)	(-50)	(-50)	(-50)	(-50)
				(-50)	(-50)	(-50)	(-50)	(-50)	(-50)	(-50)	(-50)	(-50)	(-50)	(-50)	(-50)	(-50)	(-50)	(-50)	(-50)	(-50)	(-50)
				(-75) (-75) (-75)>;

			PS_Config_Lmt_PenTipX_FW_Raw_P = <
				570 570 570 570 570 570 570 570 570 570 570 570 570 570 570 570 570 570 570 570 570 570 570 570 570 570 570 570 570 570 570 570
				570 570 570 570 570 570 570 570 570 570 570 570 570 570 570 570 570 570 570 570 570 570 570 570 570 570 570 570 570 570 570 570
				570 570 570 570 570 570 570 570 570 570 570 570 570 570 570 570 570 570 570 570 570 570 570 570 570 570 570 570 570 570 570 570
				570 570 570 570 570 570 570 570 570 570 570 570 570 570 570 570 570 570 570 570 570 570 570 570 570 570 570 570 570 570 570 570
				570 570 570 570 570 570 570 570 570 570 570 570 570 570 570 570 570 570 570 570 570 570 570 570 570 570 570 570 570 570 570 570
				570 570 570 570 570 570 570 570 570 570 570 570 570 570 570 570 570 570 570 570 570 570 570 570 570 570 570 570 570 570 570 570>;

			PS_Config_Lmt_PenTipX_FW_Raw_N = <
				(-570) (-570) (-570) (-570) (-570) (-570) (-570) (-570) (-570) (-570) (-570) (-570) (-570) (-570) (-570) (-570) (-570) (-570) (-570) (-570) (-570) (-570) (-570) (-570) (-570) (-570) (-570) (-570) (-570) (-570) (-570) (-570)
				(-570) (-570) (-570) (-570) (-570) (-570) (-570) (-570) (-570) (-570) (-570) (-570) (-570) (-570) (-570) (-570) (-570) (-570) (-570) (-570) (-570) (-570) (-570) (-570) (-570) (-570) (-570) (-570) (-570) (-570) (-570) (-570)
				(-570) (-570) (-570) (-570) (-570) (-570) (-570) (-570) (-570) (-570) (-570) (-570) (-570) (-570) (-570) (-570) (-570) (-570) (-570) (-570) (-570) (-570) (-570) (-570) (-570) (-570) (-570) (-570) (-570) (-570) (-570) (-570)
				(-570) (-570) (-570) (-570) (-570) (-570) (-570) (-570) (-570) (-570) (-570) (-570) (-570) (-570) (-570) (-570) (-570) (-570) (-570) (-570) (-570) (-570) (-570) (-570) (-570) (-570) (-570) (-570) (-570) (-570) (-570) (-570)
				(-570) (-570) (-570) (-570) (-570) (-570) (-570) (-570) (-570) (-570) (-570) (-570) (-570) (-570) (-570) (-570) (-570) (-570) (-570) (-570) (-570) (-570) (-570) (-570) (-570) (-570) (-570) (-570) (-570) (-570) (-570) (-570)
				(-570) (-570) (-570) (-570) (-570) (-570) (-570) (-570) (-570) (-570) (-570) (-570) (-570) (-570) (-570) (-570) (-570) (-570) (-570) (-570) (-570) (-570) (-570) (-570) (-570) (-570) (-570) (-570) (-570) (-570) (-570) (-570)>;

			PS_Config_Lmt_PenTipY_FW_Raw_P = <
				570 570 570 570
				570 570 570 570
				570 570 570 570
				570 570 570 570
				570 570 570 570
				570 570 570 570
				570 570 570 570
				570 570 570 570
				570 570 570 570
				570 570 570 570
				570 570 570 570
				570 570 570 570
				570 570 570 570
				570 570 570 570
				570 570 570 570
				570 570 570 570
				570 570 570 570
				570 570 570 570
				570 570 570 570
				570 570 570 570
				570 570 570 570
				570 570 570 570
				570 570 570 570
				570 570 570 570
				570 570 570 570
				570 570 570 570
				570 570 570 570
				570 570 570 570
				570 570 570 570
				570 570 570 570
				570 570 570 570
				570 570 570 570
				570 570 570 570
				570 570 570 570
				570 570 570 570
				570 570 570 570
				570 570 570 570
				570 570 570 570
				570 570 570 570
				570 570 570 570
				570 570 570 570
				570 570 570 570
				570 570 570 570
				570 570 570 570
				570 570 570 570
				570 570 570 570
				570 570 570 570
				570 570 570 570
				570 570 570 570
				570 570 570 570>;

			PS_Config_Lmt_PenTipY_FW_Raw_N = <
				(-570) (-570) (-570) (-570)
				(-570) (-570) (-570) (-570)
				(-570) (-570) (-570) (-570)
				(-570) (-570) (-570) (-570)
				(-570) (-570) (-570) (-570)
				(-570) (-570) (-570) (-570)
				(-570) (-570) (-570) (-570)
				(-570) (-570) (-570) (-570)
				(-570) (-570) (-570) (-570)
				(-570) (-570) (-570) (-570)
				(-570) (-570) (-570) (-570)
				(-570) (-570) (-570) (-570)
				(-570) (-570) (-570) (-570)
				(-570) (-570) (-570) (-570)
				(-570) (-570) (-570) (-570)
				(-570) (-570) (-570) (-570)
				(-570) (-570) (-570) (-570)
				(-570) (-570) (-570) (-570)
				(-570) (-570) (-570) (-570)
				(-570) (-570) (-570) (-570)
				(-570) (-570) (-570) (-570)
				(-570) (-570) (-570) (-570)
				(-570) (-570) (-570) (-570)
				(-570) (-570) (-570) (-570)
				(-570) (-570) (-570) (-570)
				(-570) (-570) (-570) (-570)
				(-570) (-570) (-570) (-570)
				(-570) (-570) (-570) (-570)
				(-570) (-570) (-570) (-570)
				(-570) (-570) (-570) (-570)
				(-570) (-570) (-570) (-570)
				(-570) (-570) (-570) (-570)
				(-570) (-570) (-570) (-570)
				(-570) (-570) (-570) (-570)
				(-570) (-570) (-570) (-570)
				(-570) (-570) (-570) (-570)
				(-570) (-570) (-570) (-570)
				(-570) (-570) (-570) (-570)
				(-570) (-570) (-570) (-570)
				(-570) (-570) (-570) (-570)
				(-570) (-570) (-570) (-570)
				(-570) (-570) (-570) (-570)
				(-570) (-570) (-570) (-570)
				(-570) (-570) (-570) (-570)
				(-570) (-570) (-570) (-570)
				(-570) (-570) (-570) (-570)
				(-570) (-570) (-570) (-570)
				(-570) (-570) (-570) (-570)
				(-570) (-570) (-570) (-570)
				(-570) (-570) (-570) (-570)>;

			PS_Config_Lmt_PenRingX_FW_Raw_P = <
				570 570 570 570 570 570 570 570 570 570 570 570 570 570 570 570 570 570 570 570 570 570 570 570 570 570 570 570 570 570 570 570
				570 570 570 570 570 570 570 570 570 570 570 570 570 570 570 570 570 570 570 570 570 570 570 570 570 570 570 570 570 570 570 570
				570 570 570 570 570 570 570 570 570 570 570 570 570 570 570 570 570 570 570 570 570 570 570 570 570 570 570 570 570 570 570 570
				570 570 570 570 570 570 570 570 570 570 570 570 570 570 570 570 570 570 570 570 570 570 570 570 570 570 570 570 570 570 570 570
				570 570 570 570 570 570 570 570 570 570 570 570 570 570 570 570 570 570 570 570 570 570 570 570 570 570 570 570 570 570 570 570
				570 570 570 570 570 570 570 570 570 570 570 570 570 570 570 570 570 570 570 570 570 570 570 570 570 570 570 570 570 570 570 570>;

			PS_Config_Lmt_PenRingX_FW_Raw_N = <
				(-570) (-570) (-570) (-570) (-570) (-570) (-570) (-570) (-570) (-570) (-570) (-570) (-570) (-570) (-570) (-570) (-570) (-570) (-570) (-570) (-570) (-570) (-570) (-570) (-570) (-570) (-570) (-570) (-570) (-570) (-570) (-570)
				(-570) (-570) (-570) (-570) (-570) (-570) (-570) (-570) (-570) (-570) (-570) (-570) (-570) (-570) (-570) (-570) (-570) (-570) (-570) (-570) (-570) (-570) (-570) (-570) (-570) (-570) (-570) (-570) (-570) (-570) (-570) (-570)
				(-570) (-570) (-570) (-570) (-570) (-570) (-570) (-570) (-570) (-570) (-570) (-570) (-570) (-570) (-570) (-570) (-570) (-570) (-570) (-570) (-570) (-570) (-570) (-570) (-570) (-570) (-570) (-570) (-570) (-570) (-570) (-570)
				(-570) (-570) (-570) (-570) (-570) (-570) (-570) (-570) (-570) (-570) (-570) (-570) (-570) (-570) (-570) (-570) (-570) (-570) (-570) (-570) (-570) (-570) (-570) (-570) (-570) (-570) (-570) (-570) (-570) (-570) (-570) (-570)
				(-570) (-570) (-570) (-570) (-570) (-570) (-570) (-570) (-570) (-570) (-570) (-570) (-570) (-570) (-570) (-570) (-570) (-570) (-570) (-570) (-570) (-570) (-570) (-570) (-570) (-570) (-570) (-570) (-570) (-570) (-570) (-570)
				(-570) (-570) (-570) (-570) (-570) (-570) (-570) (-570) (-570) (-570) (-570) (-570) (-570) (-570) (-570) (-570) (-570) (-570) (-570) (-570) (-570) (-570) (-570) (-570) (-570) (-570) (-570) (-570) (-570) (-570) (-570) (-570)>;

			PS_Config_Lmt_PenRingY_FW_Raw_P = <
				570 570 570 570
				570 570 570 570
				570 570 570 570
				570 570 570 570
				570 570 570 570
				570 570 570 570
				570 570 570 570
				570 570 570 570
				570 570 570 570
				570 570 570 570
				570 570 570 570
				570 570 570 570
				570 570 570 570
				570 570 570 570
				570 570 570 570
				570 570 570 570
				570 570 570 570
				570 570 570 570
				570 570 570 570
				570 570 570 570
				570 570 570 570
				570 570 570 570
				570 570 570 570
				570 570 570 570
				570 570 570 570
				570 570 570 570
				570 570 570 570
				570 570 570 570
				570 570 570 570
				570 570 570 570
				570 570 570 570
				570 570 570 570
				570 570 570 570
				570 570 570 570
				570 570 570 570
				570 570 570 570
				570 570 570 570
				570 570 570 570
				570 570 570 570
				570 570 570 570
				570 570 570 570
				570 570 570 570
				570 570 570 570
				570 570 570 570
				570 570 570 570
				570 570 570 570
				570 570 570 570
				570 570 570 570
				570 570 570 570
				570 570 570 570>;

			PS_Config_Lmt_PenRingY_FW_Raw_N = <
				(-570) (-570) (-570) (-570)
				(-570) (-570) (-570) (-570)
				(-570) (-570) (-570) (-570)
				(-570) (-570) (-570) (-570)
				(-570) (-570) (-570) (-570)
				(-570) (-570) (-570) (-570)
				(-570) (-570) (-570) (-570)
				(-570) (-570) (-570) (-570)
				(-570) (-570) (-570) (-570)
				(-570) (-570) (-570) (-570)
				(-570) (-570) (-570) (-570)
				(-570) (-570) (-570) (-570)
				(-570) (-570) (-570) (-570)
				(-570) (-570) (-570) (-570)
				(-570) (-570) (-570) (-570)
				(-570) (-570) (-570) (-570)
				(-570) (-570) (-570) (-570)
				(-570) (-570) (-570) (-570)
				(-570) (-570) (-570) (-570)
				(-570) (-570) (-570) (-570)
				(-570) (-570) (-570) (-570)
				(-570) (-570) (-570) (-570)
				(-570) (-570) (-570) (-570)
				(-570) (-570) (-570) (-570)
				(-570) (-570) (-570) (-570)
				(-570) (-570) (-570) (-570)
				(-570) (-570) (-570) (-570)
				(-570) (-570) (-570) (-570)
				(-570) (-570) (-570) (-570)
				(-570) (-570) (-570) (-570)
				(-570) (-570) (-570) (-570)
				(-570) (-570) (-570) (-570)
				(-570) (-570) (-570) (-570)
				(-570) (-570) (-570) (-570)
				(-570) (-570) (-570) (-570)
				(-570) (-570) (-570) (-570)
				(-570) (-570) (-570) (-570)
				(-570) (-570) (-570) (-570)
				(-570) (-570) (-570) (-570)
				(-570) (-570) (-570) (-570)
				(-570) (-570) (-570) (-570)
				(-570) (-570) (-570) (-570)
				(-570) (-570) (-570) (-570)
				(-570) (-570) (-570) (-570)
				(-570) (-570) (-570) (-570)
				(-570) (-570) (-570) (-570)
				(-570) (-570) (-570) (-570)
				(-570) (-570) (-570) (-570)
				(-570) (-570) (-570) (-570)
				(-570) (-570) (-570) (-570)>;

			PS_Config_Lmt_PenTipX_FW_Diff_P = <
				870 870 870 870 870 870 870 870 870 870 870 870 870 870 870 870 870 870 870 870 870 870 870 870 870 870 870 870 870 870 870 870
				870 870 870 870 870 870 870 870 870 870 870 870 870 870 870 870 870 870 870 870 870 870 870 870 870 870 870 870 870 870 870 870
				870 870 870 870 870 870 870 870 870 870 870 870 870 870 870 870 870 870 870 870 870 870 870 870 870 870 870 870 870 870 870 870
				870 870 870 870 870 870 870 870 870 870 870 870 870 870 870 870 870 870 870 870 870 870 870 870 870 870 870 870 870 870 870 870
				870 870 870 870 870 870 870 870 870 870 870 870 870 870 870 870 870 870 870 870 870 870 870 870 870 870 870 870 870 870 870 870
				870 870 870 870 870 870 870 870 870 870 870 870 870 870 870 870 870 870 870 870 870 870 870 870 870 870 870 870 870 870 870 870>;

			PS_Config_Lmt_PenTipX_FW_Diff_N = <
				(-870) (-870) (-870) (-870) (-870) (-870) (-870) (-870) (-870) (-870) (-870) (-870) (-870) (-870) (-870) (-870) (-870) (-870) (-870) (-870) (-870) (-870) (-870) (-870) (-870) (-870) (-870) (-870) (-870) (-870) (-870) (-870)
				(-870) (-870) (-870) (-870) (-870) (-870) (-870) (-870) (-870) (-870) (-870) (-870) (-870) (-870) (-870) (-870) (-870) (-870) (-870) (-870) (-870) (-870) (-870) (-870) (-870) (-870) (-870) (-870) (-870) (-870) (-870) (-870)
				(-870) (-870) (-870) (-870) (-870) (-870) (-870) (-870) (-870) (-870) (-870) (-870) (-870) (-870) (-870) (-870) (-870) (-870) (-870) (-870) (-870) (-870) (-870) (-870) (-870) (-870) (-870) (-870) (-870) (-870) (-870) (-870)
				(-870) (-870) (-870) (-870) (-870) (-870) (-870) (-870) (-870) (-870) (-870) (-870) (-870) (-870) (-870) (-870) (-870) (-870) (-870) (-870) (-870) (-870) (-870) (-870) (-870) (-870) (-870) (-870) (-870) (-870) (-870) (-870)
				(-870) (-870) (-870) (-870) (-870) (-870) (-870) (-870) (-870) (-870) (-870) (-870) (-870) (-870) (-870) (-870) (-870) (-870) (-870) (-870) (-870) (-870) (-870) (-870) (-870) (-870) (-870) (-870) (-870) (-870) (-870) (-870)
				(-870) (-870) (-870) (-870) (-870) (-870) (-870) (-870) (-870) (-870) (-870) (-870) (-870) (-870) (-870) (-870) (-870) (-870) (-870) (-870) (-870) (-870) (-870) (-870) (-870) (-870) (-870) (-870) (-870) (-870) (-870) (-870)>;

			PS_Config_Lmt_PenTipY_FW_Diff_P = <
				870 870 870 870
				870 870 870 870
				870 870 870 870
				870 870 870 870
				870 870 870 870
				870 870 870 870
				870 870 870 870
				870 870 870 870
				870 870 870 870
				870 870 870 870
				870 870 870 870
				870 870 870 870
				870 870 870 870
				870 870 870 870
				870 870 870 870
				870 870 870 870
				870 870 870 870
				870 870 870 870
				870 870 870 870
				870 870 870 870
				870 870 870 870
				870 870 870 870
				870 870 870 870
				870 870 870 870
				870 870 870 870
				870 870 870 870
				870 870 870 870
				870 870 870 870
				870 870 870 870
				870 870 870 870
				870 870 870 870
				870 870 870 870
				870 870 870 870
				870 870 870 870
				870 870 870 870
				870 870 870 870
				870 870 870 870
				870 870 870 870
				870 870 870 870
				870 870 870 870
				870 870 870 870
				870 870 870 870
				870 870 870 870
				870 870 870 870
				870 870 870 870
				870 870 870 870
				870 870 870 870
				870 870 870 870
				870 870 870 870
				870 870 870 870>;

			PS_Config_Lmt_PenTipY_FW_Diff_N = <
				(-870) (-870) (-870) (-870)
				(-870) (-870) (-870) (-870)
				(-870) (-870) (-870) (-870)
				(-870) (-870) (-870) (-870)
				(-870) (-870) (-870) (-870)
				(-870) (-870) (-870) (-870)
				(-870) (-870) (-870) (-870)
				(-870) (-870) (-870) (-870)
				(-870) (-870) (-870) (-870)
				(-870) (-870) (-870) (-870)
				(-870) (-870) (-870) (-870)
				(-870) (-870) (-870) (-870)
				(-870) (-870) (-870) (-870)
				(-870) (-870) (-870) (-870)
				(-870) (-870) (-870) (-870)
				(-870) (-870) (-870) (-870)
				(-870) (-870) (-870) (-870)
				(-870) (-870) (-870) (-870)
				(-870) (-870) (-870) (-870)
				(-870) (-870) (-870) (-870)
				(-870) (-870) (-870) (-870)
				(-870) (-870) (-870) (-870)
				(-870) (-870) (-870) (-870)
				(-870) (-870) (-870) (-870)
				(-870) (-870) (-870) (-870)
				(-870) (-870) (-870) (-870)
				(-870) (-870) (-870) (-870)
				(-870) (-870) (-870) (-870)
				(-870) (-870) (-870) (-870)
				(-870) (-870) (-870) (-870)
				(-870) (-870) (-870) (-870)
				(-870) (-870) (-870) (-870)
				(-870) (-870) (-870) (-870)
				(-870) (-870) (-870) (-870)
				(-870) (-870) (-870) (-870)
				(-870) (-870) (-870) (-870)
				(-870) (-870) (-870) (-870)
				(-870) (-870) (-870) (-870)
				(-870) (-870) (-870) (-870)
				(-870) (-870) (-870) (-870)
				(-870) (-870) (-870) (-870)
				(-870) (-870) (-870) (-870)
				(-870) (-870) (-870) (-870)
				(-870) (-870) (-870) (-870)
				(-870) (-870) (-870) (-870)
				(-870) (-870) (-870) (-870)
				(-870) (-870) (-870) (-870)
				(-870) (-870) (-870) (-870)
				(-870) (-870) (-870) (-870)
				(-870) (-870) (-870) (-870)>;

			PS_Config_Lmt_PenRingX_FW_Diff_P = <
				870 870 870 870 870 870 870 870 870 870 870 870 870 870 870 870 870 870 870 870 870 870 870 870 870 870 870 870 870 870 870 870
				870 870 870 870 870 870 870 870 870 870 870 870 870 870 870 870 870 870 870 870 870 870 870 870 870 870 870 870 870 870 870 870
				870 870 870 870 870 870 870 870 870 870 870 870 870 870 870 870 870 870 870 870 870 870 870 870 870 870 870 870 870 870 870 870
				870 870 870 870 870 870 870 870 870 870 870 870 870 870 870 870 870 870 870 870 870 870 870 870 870 870 870 870 870 870 870 870
				870 870 870 870 870 870 870 870 870 870 870 870 870 870 870 870 870 870 870 870 870 870 870 870 870 870 870 870 870 870 870 870
				870 870 870 870 870 870 870 870 870 870 870 870 870 870 870 870 870 870 870 870 870 870 870 870 870 870 870 870 870 870 870 870>;

			PS_Config_Lmt_PenRingX_FW_Diff_N = <
				(-870) (-870) (-870) (-870) (-870) (-870) (-870) (-870) (-870) (-870) (-870) (-870) (-870) (-870) (-870) (-870) (-870) (-870) (-870) (-870) (-870) (-870) (-870) (-870) (-870) (-870) (-870) (-870) (-870) (-870) (-870) (-870)
				(-870) (-870) (-870) (-870) (-870) (-870) (-870) (-870) (-870) (-870) (-870) (-870) (-870) (-870) (-870) (-870) (-870) (-870) (-870) (-870) (-870) (-870) (-870) (-870) (-870) (-870) (-870) (-870) (-870) (-870) (-870) (-870)
				(-870) (-870) (-870) (-870) (-870) (-870) (-870) (-870) (-870) (-870) (-870) (-870) (-870) (-870) (-870) (-870) (-870) (-870) (-870) (-870) (-870) (-870) (-870) (-870) (-870) (-870) (-870) (-870) (-870) (-870) (-870) (-870)
				(-870) (-870) (-870) (-870) (-870) (-870) (-870) (-870) (-870) (-870) (-870) (-870) (-870) (-870) (-870) (-870) (-870) (-870) (-870) (-870) (-870) (-870) (-870) (-870) (-870) (-870) (-870) (-870) (-870) (-870) (-870) (-870)
				(-870) (-870) (-870) (-870) (-870) (-870) (-870) (-870) (-870) (-870) (-870) (-870) (-870) (-870) (-870) (-870) (-870) (-870) (-870) (-870) (-870) (-870) (-870) (-870) (-870) (-870) (-870) (-870) (-870) (-870) (-870) (-870)
				(-870) (-870) (-870) (-870) (-870) (-870) (-870) (-870) (-870) (-870) (-870) (-870) (-870) (-870) (-870) (-870) (-870) (-870) (-870) (-870) (-870) (-870) (-870) (-870) (-870) (-870) (-870) (-870) (-870) (-870) (-870) (-870)>;

			PS_Config_Lmt_PenRingY_FW_Diff_P = <
				870 870 870 870
				870 870 870 870
				870 870 870 870
				870 870 870 870
				870 870 870 870
				870 870 870 870
				870 870 870 870
				870 870 870 870
				870 870 870 870
				870 870 870 870
				870 870 870 870
				870 870 870 870
				870 870 870 870
				870 870 870 870
				870 870 870 870
				870 870 870 870
				870 870 870 870
				870 870 870 870
				870 870 870 870
				870 870 870 870
				870 870 870 870
				870 870 870 870
				870 870 870 870
				870 870 870 870
				870 870 870 870
				870 870 870 870
				870 870 870 870
				870 870 870 870
				870 870 870 870
				870 870 870 870
				870 870 870 870
				870 870 870 870
				870 870 870 870
				870 870 870 870
				870 870 870 870
				870 870 870 870
				870 870 870 870
				870 870 870 870
				870 870 870 870
				870 870 870 870
				870 870 870 870
				870 870 870 870
				870 870 870 870
				870 870 870 870
				870 870 870 870
				870 870 870 870
				870 870 870 870
				870 870 870 870
				870 870 870 870
				870 870 870 870>;

			PS_Config_Lmt_PenRingY_FW_Diff_N = <
				(-870) (-870) (-870) (-870)
				(-870) (-870) (-870) (-870)
				(-870) (-870) (-870) (-870)
				(-870) (-870) (-870) (-870)
				(-870) (-870) (-870) (-870)
				(-870) (-870) (-870) (-870)
				(-870) (-870) (-870) (-870)
				(-870) (-870) (-870) (-870)
				(-870) (-870) (-870) (-870)
				(-870) (-870) (-870) (-870)
				(-870) (-870) (-870) (-870)
				(-870) (-870) (-870) (-870)
				(-870) (-870) (-870) (-870)
				(-870) (-870) (-870) (-870)
				(-870) (-870) (-870) (-870)
				(-870) (-870) (-870) (-870)
				(-870) (-870) (-870) (-870)
				(-870) (-870) (-870) (-870)
				(-870) (-870) (-870) (-870)
				(-870) (-870) (-870) (-870)
				(-870) (-870) (-870) (-870)
				(-870) (-870) (-870) (-870)
				(-870) (-870) (-870) (-870)
				(-870) (-870) (-870) (-870)
				(-870) (-870) (-870) (-870)
				(-870) (-870) (-870) (-870)
				(-870) (-870) (-870) (-870)
				(-870) (-870) (-870) (-870)
				(-870) (-870) (-870) (-870)
				(-870) (-870) (-870) (-870)
				(-870) (-870) (-870) (-870)
				(-870) (-870) (-870) (-870)
				(-870) (-870) (-870) (-870)
				(-870) (-870) (-870) (-870)
				(-870) (-870) (-870) (-870)
				(-870) (-870) (-870) (-870)
				(-870) (-870) (-870) (-870)
				(-870) (-870) (-870) (-870)
				(-870) (-870) (-870) (-870)
				(-870) (-870) (-870) (-870)
				(-870) (-870) (-870) (-870)
				(-870) (-870) (-870) (-870)
				(-870) (-870) (-870) (-870)
				(-870) (-870) (-870) (-870)
				(-870) (-870) (-870) (-870)
				(-870) (-870) (-870) (-870)
				(-870) (-870) (-870) (-870)
				(-870) (-870) (-870) (-870)
				(-870) (-870) (-870) (-870)
				(-870) (-870) (-870) (-870)>;

			PS_Config_Diff_Test_Frame = <50>;
		};

		/*for Xiaomi K19 672C JDI6.497" Truly Module*/
		novatek-mp-criteria-5956@0 {
			#address-cells = <1>;
			#size-cells = <0>;
			compatible = "novatek-mp-criteria-5956";

			/* MP Config */
			IC_X_CFG_SIZE = <16>;
			IC_Y_CFG_SIZE = <36>;
			IC_KEY_CFG_SIZE = <4>;
			X_Channel = <16>;
			Y_Channel = <36>;
			AIN_X = <0 1 2 3 4 5 6 7 8 9 10 11 12 13 14 15>;
			AIN_Y = <0 1 2 3 4 5 6 7 8 9 10 11 12 13 14 15 16 17 18 19 20 21 22 23 24 25 26 27 28 29 30 31 32 33 34 35>;
			//AIN_X = <0 1 2 3 4 5 6 7 8 9 10 11 12 13 14 15 16 17 18 19 20 21 22 23 24 25 26 27 28 29 30 31>;
			//AIN_Y = <0 1 2 3 4 5 6 7 8 9 10 11 12 13 14 15 16 17 18 19 20 21 22 23 24 25 26 27 28 29 30 31 32 33 34 35 36 37 38 39 40 41 42 43 44 45 46 47 48 49>;
			AIN_KEY = <0 1 2 0xFF>;

			/* MP Criteria */
			PS_Config_Lmt_Short_Rawdata_P = <
				14008 14008 14008 14008 14008 14008 14008 14008 14008 14008 14008 14008 14008 14008 14008 14008
				14008 14008 14008 14008 14008 14008 14008 14008 14008 14008 14008 14008 14008 14008 14008 14008
				14008 14008 14008 14008 14008 14008 14008 14008 14008 14008 14008 14008 14008 14008 14008 14008
				14008 14008 14008 14008 14008 14008 14008 14008 14008 14008 14008 14008 14008 14008 14008 14008
				14008 14008 14008 14008 14008 14008 14008 14008 14008 14008 14008 14008 14008 14008 14008 14008
				14008 14008 14008 14008 14008 14008 14008 14008 14008 14008 14008 14008 14008 14008 14008 14008
				14008 14008 14008 14008 14008 14008 14008 14008 14008 14008 14008 14008 14008 14008 14008 14008
				14008 14008 14008 14008 14008 14008 14008 14008 14008 14008 14008 14008 14008 14008 14008 14008
				14008 14008 14008 14008 14008 14008 14008 14008 14008 14008 14008 14008 14008 14008 14008 14008
				14008 14008 14008 14008 14008 14008 14008 14008 14008 14008 14008 14008 14008 14008 14008 14008
				14008 14008 14008 14008 14008 14008 14008 14008 14008 14008 14008 14008 14008 14008 14008 14008
				14008 14008 14008 14008 14008 14008 14008 14008 14008 14008 14008 14008 14008 14008 14008 14008
				14008 14008 14008 14008 14008 14008 14008 14008 14008 14008 14008 14008 14008 14008 14008 14008
				14008 14008 14008 14008 14008 14008 14008 14008 14008 14008 14008 14008 14008 14008 14008 14008
				14008 14008 14008 14008 14008 14008 14008 14008 14008 14008 14008 14008 14008 14008 14008 14008
				14008 14008 14008 14008 14008 14008 14008 14008 14008 14008 14008 14008 14008 14008 14008 14008
				14008 14008 14008 14008 14008 14008 14008 14008 14008 14008 14008 14008 14008 14008 14008 14008
				14008 14008 14008 14008 14008 14008 14008 14008 14008 14008 14008 14008 14008 14008 14008 14008
				14008 14008 14008 14008 14008 14008 14008 14008 14008 14008 14008 14008 14008 14008 14008 14008
				14008 14008 14008 14008 14008 14008 14008 14008 14008 14008 14008 14008 14008 14008 14008 14008
				14008 14008 14008 14008 14008 14008 14008 14008 14008 14008 14008 14008 14008 14008 14008 14008
				14008 14008 14008 14008 14008 14008 14008 14008 14008 14008 14008 14008 14008 14008 14008 14008
				14008 14008 14008 14008 14008 14008 14008 14008 14008 14008 14008 14008 14008 14008 14008 14008
				14008 14008 14008 14008 14008 14008 14008 14008 14008 14008 14008 14008 14008 14008 14008 14008
				14008 14008 14008 14008 14008 14008 14008 14008 14008 14008 14008 14008 14008 14008 14008 14008
				14008 14008 14008 14008 14008 14008 14008 14008 14008 14008 14008 14008 14008 14008 14008 14008
				14008 14008 14008 14008 14008 14008 14008 14008 14008 14008 14008 14008 14008 14008 14008 14008
				14008 14008 14008 14008 14008 14008 14008 14008 14008 14008 14008 14008 14008 14008 14008 14008
				14008 14008 14008 14008 14008 14008 14008 14008 14008 14008 14008 14008 14008 14008 14008 14008
				14008 14008 14008 14008 14008 14008 14008 14008 14008 14008 14008 14008 14008 14008 14008 14008
				14008 14008 14008 14008 14008 14008 14008 14008 14008 14008 14008 14008 14008 14008 14008 14008
				14008 14008 14008 14008 14008 14008 14008 14008 14008 14008 14008 14008 14008 14008 14008 14008
				14008 14008 14008 14008 14008 14008 14008 14008 14008 14008 14008 14008 14008 14008 14008 14008
				14008 14008 14008 14008 14008 14008 14008 14008 14008 14008 14008 14008 14008 14008 14008 14008
				14008 14008 14008 14008 14008 14008 14008 14008 14008 14008 14008 14008 14008 14008 14008 14008
				14008 14008 14008 14008 14008 14008 14008 14008 14008 14008 14008 14008 14008 14008 14008 14008
				14008 14008 14008>;

			PS_Config_Lmt_Short_Rawdata_N = <
				10100	10100	10100	10100	10100	10100	10100	10100	10100	10100	10100	10100	10100	10100	10100	10100
				10100	10100	10100	10100	10100	10100	10100	10100	10100	10100	10100	10100	10100	10100	10100	10100
				10100	10100	10100	10100	10100	10100	10100	10100	10100	10100	10100	10100	10100	10100	10100	10100
				10100	10100	10100	10100	10100	10100	10100	10100	10100	10100	10100	10100	10100	10100	10100	10100
				10100	10100	10100	10100	10100	10100	10100	10100	10100	10100	10100	10100	10100	10100	10100	10100
				10100	10100	10100	10100	10100	10100	10100	10100	10100	10100	10100	10100	10100	10100	10100	10100
				10100	10100	10100	10100	10100	10100	10100	10100	10100	10100	10100	10100	10100	10100	10100	10100
				10100	10100	10100	10100	10100	10100	10100	10100	10100	10100	10100	10100	10100	10100	10100	10100
				10100	10100	10100	10100	10100	10100	10100	10100	10100	10100	10100	10100	10100	10100	10100	10100
				10100	10100	10100	10100	10100	10100	10100	10100	10100	10100	10100	10100	10100	10100	10100	10100
				10100	10100	10100	10100	10100	10100	10100	10100	10100	10100	10100	10100	10100	10100	10100	10100
				10100	10100	10100	10100	10100	10100	10100	10100	10100	10100	10100	10100	10100	10100	10100	10100
				10100	10100	10100	10100	10100	10100	10100	10100	10100	10100	10100	10100	10100	10100	10100	10100
				10100	10100	10100	10100	10100	10100	10100	10100	10100	10100	10100	10100	10100	10100	10100	10100
				10100	10100	10100	10100	10100	10100	10100	10100	10100	10100	10100	10100	10100	10100	10100	10100
				10100	10100	10100	10100	10100	10100	10100	10100	10100	10100	10100	10100	10100	10100	10100	10100
				10100	10100	10100	10100	10100	10100	10100	10100	10100	10100	10100	10100	10100	10100	10100	10100
				10100	10100	10100	10100	10100	10100	10100	10100	10100	10100	10100	10100	10100	10100	10100	10100
				10100	10100	10100	10100	10100	10100	10100	10100	10100	10100	10100	10100	10100	10100	10100	10100
				10100	10100	10100	10100	10100	10100	10100	10100	10100	10100	10100	10100	10100	10100	10100	10100
				10100	10100	10100	10100	10100	10100	10100	10100	10100	10100	10100	10100	10100	10100	10100	10100
				10100	10100	10100	10100	10100	10100	10100	10100	10100	10100	10100	10100	10100	10100	10100	10100
				10100	10100	10100	10100	10100	10100	10100	10100	10100	10100	10100	10100	10100	10100	10100	10100
				10100	10100	10100	10100	10100	10100	10100	10100	10100	10100	10100	10100	10100	10100	10100	10100
				10100	10100	10100	10100	10100	10100	10100	10100	10100	10100	10100	10100	10100	10100	10100	10100
				10100	10100	10100	10100	10100	10100	10100	10100	10100	10100	10100	10100	10100	10100	10100	10100
				10100	10100	10100	10100	10100	10100	10100	10100	10100	10100	10100	10100	10100	10100	10100	10100
				10100	10100	10100	10100	10100	10100	10100	10100	10100	10100	10100	10100	10100	10100	10100	10100
				10100	10100	10100	10100	10100	10100	10100	10100	10100	10100	10100	10100	10100	10100	10100	10100
				10100	10100	10100	10100	10100	10100	10100	10100	10100	10100	10100	10100	10100	10100	10100	10100
				10100	10100	10100	10100	10100	10100	10100	10100	10100	10100	10100	10100	10100	10100	10100	10100
				10100	10100	10100	10100	10100	10100	10100	10100	10100	10100	10100	10100	10100	10100	10100	10100
				10100	10100	10100	10100	10100	10100	10100	10100	10100	10100	10100	10100	10100	10100	10100	10100
				10100	10100	10100	10100	10100	10100	10100	10100	10100	10100	10100	10100	10100	10100	10100	10100
				10100	10100	10100	10100	10100	10100	10100	10100	10100	10100	10100	10100	10100	10100	10100	10100
				10100	10100	10100	10100	10100	10100	10100	10100	10100	10100	10100	10100	10100	10100	10100	10100
				10000 10000 10000>;

			PS_Config_Lmt_Open_Rawdata_P = <
				3512	3907	3866	3822	3794	3788	3799	3719	3885	4004	3987	3995	3928	3921	3904	3500
				3696	3907	3841	3795	3773	3763	3775	3735	3911	3983	3963	3981	3914	3910	3917	3677
				3848	3858	3787	3728	3714	3703	3719	3715	3921	3922	3908	3920	3864	3868	3894	3833
				3857	3866	3796	3726	3710	3698	3718	3676	3879	3886	3871	3883	3838	3841	3876	3784
				3803	3829	3745	3680	3673	3654	3670	3656	3782	3796	3788	3798	3753	3775	3808	3754
				3767	3796	3703	3648	3634	3619	3631	3617	3763	3782	3777	3780	3746	3774	3806	3753
				3764	3803	3717	3648	3637	3623	3634	3620	3714	3736	3719	3736	3703	3729	3768	3719
				3726	3771	3679	3607	3596	3591	3571	3585	3701	3725	3708	3722	3691	3722	3736	3719
				3721	3763	3675	3602	3595	3578	3595	3578	3676	3694	3680	3689	3672	3697	3749	3697
				3675	3714	3626	3553	3546	3528	3546	3526	3648	3665	3655	3665	3654	3680	3740	3689
				3665	3714	3617	3556	3539	3502	3546	3523	3578	3602	3591	3593	3592	3598	3677	3630
				3648	3690	3591	3532	3516	3504	3525	3501	3560	3585	3572	3577	3581	3617	3675	3633
				3612	3658	3568	3495	3479	3470	3488	3466	3502	3528	3507	3516	3528	3553	3623	3579
				3560	3612	3525	3453	3438	3435	3445	3425	3509	3533	3518	3526	3540	3572	3640	3599
				3561	3605	3523	3449	3414	3430	3442	3420	3472	3491	3483	3488	3480	3546	3619	3581
				3515	3551	3477	3400	3389	3379	3395	3372	3428	3449	3438	3439	3460	3500	3575	3532
				3488	3529	3448	3372	3361	3354	3367	3346	3364	3389	3378	3383	3400	3453	3526	3487
				3474	3515	3430	3339	3348	3339	3350	3332	3332	3360	3350	3333	3371	3431	3505	3467
				3421	3462	3385	3332	3320	3312	3320	3299	3280	3305	3292	3297	3318	3393	3477	3445
				3381	3420	3344	3290	3278	3274	3277	3260	3203	3225	3214	3224	3241	3322	3410	3379
				3364	3397	3322	3273	3260	3252	3257	3241	3179	3194	3192	3194	3214	3294	3390	3360
				3329	3355	3260	3231	3221	3208	3214	3196	3129	3144	3126	3147	3168	3249	3347	3315
				3292	3319	3236	3189	3180	3171	3172	3157	3074	3094	3091	3099	3116	3197	3302	3274
				3257	3287	3203	3154	3148	3140	3138	3127	3039	3057	3060	3063	3080	3165	3270	3245
				3206	3228	3150	3095	3091	3084	3082	3067	3014	3029	3029	3035	3053	3134	3249	3227
				3161	3169	3106	3050	3053	3047	3043	3031	2963	2965	2980	2989	3004	3085	3204	3183
				3131	3151	3067	3015	3015	3005	3007	2989	2898	2913	2916	2920	2935	3021	3136	3120
				3105	3122	3036	2979	2984	2979	2976	2959	2851	2868	2872	2875	2895	2976	3096	3084
				3010	3045	2956	2905	2910	2905	2902	2891	2772	2802	2801	2808	2823	2906	3025	3022
				3008	3031	2938	2884	2891	2884	2881	2870	2755	2777	2777	2781	2797	2885	2998	3001
				2949	2968	2875	2818	2833	2826	2823	2808	2706	2720	2723	2728	2744	2826	2945	2948
				2906	2926	2836	2776	2791	2786	2780	2765	2637	2655	2653	2660	2675	2759	2879	2884
				2892	2913	2816	2758	2773	2767	2766	2749	2623	2640	2643	2644	2661	2751	2874	2878
				2836	2856	2759	2700	2717	2713	2714	2700	2594	2609	2611	2609	2626	2714	2839	2846
				2611	2856	2752	2695	2716	2713	2714	2697	2534	2552	2550	2550	2567	2657	2787	2570
				2724	2787	2679	2620	2643	2640	2646	2632	2515	2535	2531	2531	2548	2637	2765	2741
				5120 5120 5120>;

			PS_Config_Lmt_Open_Rawdata_N = <
				1505	1674	1657	1638	1626	1623	1628	1594	1665	1716	1708	1712	1683	1680	1673	1500
				1584	1674	1646	1626	1617	1612	1618	1600	1676	1707	1698	1706	1677	1675	1678	1576
				1649	1653	1623	1597	1591	1587	1594	1592	1680	1681	1675	1680	1656	1657	1669	1642
				1653	1657	1627	1597	1590	1585	1593	1575	1662	1665	1659	1664	1645	1646	1661	1621
				1630	1641	1605	1577	1574	1566	1573	1567	1621	1627	1623	1627	1608	1618	1632	1609
				1614	1627	1587	1563	1557	1551	1556	1550	1612	1621	1618	1620	1605	1617	1631	1608
				1613	1630	1593	1563	1558	1552	1557	1551	1591	1601	1594	1601	1587	1598	1615	1594
				1597	1616	1576	1546	1541	1539	1530	1536	1586	1596	1589	1595	1582	1595	1601	1594
				1594	1612	1575	1543	1540	1533	1540	1533	1575	1583	1577	1581	1573	1584	1606	1584
				1575	1591	1554	1522	1519	1512	1519	1511	1563	1570	1566	1570	1566	1577	1603	1581
				1570	1591	1550	1524	1516	1501	1519	1510	1533	1543	1539	1540	1539	1542	1576	1555
				1563	1581	1539	1513	1507	1501	1510	1500	1525	1536	1531	1533	1534	1550	1575	1557
				1548	1567	1529	1498	1491	1487	1495	1485	1501	1512	1503	1507	1512	1522	1552	1534
				1525	1548	1510	1480	1473	1472	1476	1468	1504	1514	1507	1511	1517	1531	1560	1542
				1526	1545	1510	1478	1463	1470	1475	1465	1488	1496	1492	1495	1491	1519	1551	1534
				1506	1522	1490	1457	1452	1448	1455	1445	1469	1478	1473	1474	1483	1500	1532	1513
				1495	1512	1477	1445	1440	1437	1443	1434	1441	1452	1447	1450	1457	1480	1511	1494
				1489	1506	1470	1431	1435	1431	1435	1428	1428	1440	1435	1428	1444	1470	1502	1486
				1466	1483	1450	1428	1423	1419	1423	1414	1405	1416	1411	1413	1422	1454	1490	1476
				1449	1465	1433	1410	1405	1403	1404	1397	1372	1382	1377	1381	1389	1423	1461	1448
				1441	1456	1423	1402	1397	1393	1396	1389	1362	1369	1368	1369	1377	1411	1453	1440
				1426	1438	1397	1384	1380	1375	1377	1369	1341	1347	1339	1348	1357	1392	1434	1420
				1411	1422	1387	1366	1363	1359	1359	1353	1317	1326	1324	1328	1335	1370	1415	1403
				1396	1408	1372	1351	1349	1345	1345	1340	1302	1310	1311	1312	1320	1356	1401	1390
				1374	1383	1350	1326	1324	1321	1321	1314	1291	1298	1298	1300	1308	1343	1392	1383
				1354	1358	1331	1307	1308	1306	1304	1299	1270	1270	1277	1281	1287	1322	1373	1364
				1342	1350	1314	1292	1292	1288	1288	1281	1242	1248	1249	1251	1258	1294	1344	1337
				1330	1338	1301	1276	1279	1276	1275	1268	1222	1229	1231	1232	1240	1275	1327	1321
				1290	1305	1267	1245	1247	1245	1243	1239	1188	1201	1200	1203	1210	1245	1296	1295
				1289	1299	1259	1236	1239	1236	1234	1230	1180	1190	1190	1192	1198	1236	1285	1286
				1264	1272	1232	1207	1214	1211	1210	1203	1159	1165	1167	1169	1176	1211	1262	1263
				1245	1254	1215	1189	1196	1194	1191	1185	1130	1138	1137	1140	1146	1182	1234	1236
				1239	1248	1207	1182	1188	1186	1185	1178	1124	1131	1132	1133	1140	1179	1231	1233
				1215	1224	1182	1157	1164	1162	1163	1157	1111	1118	1119	1118	1125	1163	1216	1219
				1119	1224	1179	1155	1164	1162	1163	1156	1086	1093	1093	1093	1100	1138	1194	1101
				1167	1194	1148	1123	1132	1131	1134	1128	1078	1086	1084	1084	1092	1130	1185	1174
				(-511) (-511) (-511)>;

			PS_Config_Lmt_FW_Rawdata_P = <
				1121	1135	1129	1131	1127	1122	1122	1124	1141	1135	1135	1113	1104	1108	1093	1092
				1131	1141	1146	1142	1143	1129	1132	1100	1121	1143	1129	1142	1134	1122	1092	1136
				1128	1097	1099	1110	1090	1097	1110	1101	1100	1094	1101	1099	1101	1135	1138	1094
				1134	1107	1113	1108	1107	1106	1111	1104	1134	1129	1131	1134	1134	1120	1121	1129
				1114	1096	1100	1101	1107	1127	1103	1106	1132	1129	1132	1138	1131	1113	1103	1138
				1142	1107	1107	1121	1104	1094	1125	1125	1129	1125	1135	1141	1135	1128	1128	1128
				1106	1135	1131	1120	1136	1139	1103	1094	1094	1096	1136	1104	1111	1128	1139	1099
				1121	1092	1089	1089	1096	1093	1093	1103	1110	1127	1131	1125	1127	1121	1120	1132
				1114	1107	1110	1118	1108	1110	1113	1115	1104	1107	1132	1136	1141	1134	1110	1134
				1110	1131	1113	1110	1110	1111	1101	1110	1090	1104	1124	1122	1118	1146	1149	1129
				1155	1142	1138	1141	1141	1146	1122	1128	1120	1120	1110	1113	1106	1096	1092	1118
				1117	1111	1113	1108	1107	1113	1120	1111	1146	1145	1145	1148	1138	1132	1114	1134
				1108	1149	1131	1142	1142	1143	1125	1131	1124	1121	1134	1138	1132	1129	1115	1097
				1122	1094	1100	1096	1110	1103	1106	1110	1129	1131	1124	1139	1120	1117	1113	1121
				1139	1129	1136	1125	1132	1135	1136	1136	1143	1138	1127	1141	1127	1118	1110	1141
				1096	1150	1111	1141	1121	1125	1110	1087	1117	1115	1122	1120	1114	1121	1104	1117
				1115	1110	1120	1110	1113	1114	1124	1127	1132	1125	1114	1120	1111	1114	1099	1129
				1110	1117	1125	1121	1128	1135	1089	1103	1135	1135	1138	1129	1129	1129	1129	1141
				1110	1117	1100	1096	1110	1106	1122	1134	1118	1115	1108	1107	1107	1107	1101	1136
				1135	1113	1113	1117	1114	1115	1129	1111	1103	1090	1101	1104	1097	1096	1107	1117
				1106	1118	1115	1115	1107	1101	1096	1101	1132	1094	1096	1086	1094	1092	1099	1113
				1113	1103	1101	1099	1107	1103	1100	1120	1114	1110	1122	1122	1122	1127	1128	1128
				1117	1101	1093	1094	1096	1103	1110	1115	1103	1125	1127	1134	1142	1134	1141	1110
				1115	1115	1080	1080	1083	1087	1089	1113	1115	1113	1117	1121	1124	1124	1118	1120
				1134	1110	1107	1111	1108	1121	1118	1125	1125	1111	1117	1103	1104	1110	1104	1134
				1120	1111	1107	1099	1101	1108	1104	1135	1103	1114	1117	1135	1135	1115	1120	1104
				1134	1160	1169	1153	1169	1122	1136	1080	1113	1134	1135	1129	1134	1138	1134	1104
				1099	1118	1111	1122	1122	1103	1103	1129	1104	1100	1100	1122	1129	1131	1132	1110
				1128	1120	1111	1110	1106	1125	1121	1142	1111	1115	1114	1111	1108	1117	1103	1101
				1099	1111	1103	1106	1117	1096	1099	1128	1107	1108	1106	1124	1125	1108	1114	1108
				1111	1092	1094	1093	1090	1110	1107	1120	1138	1090	1089	1075	1079	1087	1087	1111
				1111	1118	1122	1108	1125	1118	1115	1106	1106	1117	1113	1110	1113	1106	1125	1100
				1136	1106	1125	1127	1115	1132	1141	1125	1107	1121	1117	1120	1117	1121	1118	1128
				1129	1124	1125	1117	1120	1124	1108	1117	1092	1142	1135	1131	1135	1135	1122	1113
				1106	1103	1103	1108	1113	1108	1113	1129	1100	1132	1134	1146	1148	1148	1135	1139
				1108	1114	1111	1106	1097	1111	1122	1115	1134	1117	1096	1099	1100	1106	1106	1118
				2560 2560 2560>;

			PS_Config_Lmt_FW_Rawdata_N = <
				480	486	484	484	483	481	481	481	489	486	486	477	473	475	468	468
				484	489	491	489	490	484	485	471	480	490	484	489	486	481	468	487
				483	470	471	475	467	470	475	472	471	469	472	471	472	486	487	469
				486	474	477	475	474	474	476	473	486	484	484	486	486	480	480	484
				477	469	471	472	474	483	472	474	485	484	485	487	484	477	472	487
				489	474	474	480	473	469	482	482	484	482	486	489	486	483	483	483
				474	486	484	480	487	488	472	469	469	469	487	473	476	483	488	471
				480	468	466	466	469	468	468	472	475	483	484	482	483	480	480	485
				477	474	475	479	475	475	477	478	473	474	485	487	489	486	475	486
				475	484	477	475	475	476	472	475	467	473	481	481	479	491	492	484
				495	489	487	489	489	491	481	483	480	480	475	477	474	469	468	479
				478	476	477	475	474	477	480	476	491	490	490	492	487	485	477	486
				475	492	484	489	489	490	482	484	481	480	486	487	485	484	478	470
				481	469	471	469	475	472	474	475	484	484	481	488	480	478	477	480
				488	484	487	482	485	486	487	487	490	487	483	489	483	479	475	489
				469	493	476	489	480	482	475	466	478	478	481	480	477	480	473	478
				478	475	480	475	477	477	481	483	485	482	477	480	476	477	471	484
				475	478	482	480	483	486	466	472	486	486	487	484	484	484	484	489
				475	478	471	469	475	474	481	486	479	478	475	474	474	474	472	487
				486	477	477	478	477	478	484	476	472	467	472	473	470	469	474	478
				474	479	478	478	474	472	469	472	485	469	469	465	469	468	471	477
				477	472	472	471	474	472	471	480	477	475	481	481	481	483	483	483
				478	472	468	469	469	472	475	478	472	482	483	486	489	486	489	475
				478	478	463	463	464	466	466	477	478	477	478	480	481	481	479	480
				486	475	474	476	475	480	479	482	482	476	478	472	473	475	473	486
				480	476	474	471	472	475	473	486	472	477	478	486	486	478	480	473
				486	497	501	494	501	481	487	463	477	486	486	484	486	487	486	473
				471	479	476	481	481	472	472	484	473	471	471	481	484	484	485	475
				483	480	476	475	474	482	480	489	476	478	477	476	475	478	472	472
				471	476	472	474	478	469	471	483	474	475	474	481	482	475	477	475
				476	468	469	468	467	475	474	480	487	467	466	460	462	466	466	476
				476	479	481	475	482	479	478	474	474	478	477	475	477	474	482	471
				487	474	482	483	478	485	489	482	474	480	478	480	478	480	479	483
				484	481	482	478	480	481	475	478	468	489	486	484	486	486	481	477
				474	472	472	475	477	475	477	484	471	485	486	491	492	492	486	488
				475	477	476	474	470	476	481	478	486	478	469	471	471	474	474	479
				240 240 240>;

			PS_Config_Lmt_FW_CC_P = <
				49	48	48	48	48	49	49	49	49	49	49	49	48	48	48	49
				51	49	49	49	49	49	49	49	49	49	49	49	48	48	48	49
				49	49	49	49	49	49	49	49	49	49	49	49	49	49	49	49
				49	49	49	49	49	49	49	49	49	49	49	49	49	49	49	49
				49	49	49	49	49	49	49	49	49	49	49	49	49	49	49	49
				51	49	49	49	49	49	49	49	49	49	49	49	49	49	49	49
				49	49	49	49	49	49	49	49	49	49	49	49	49	49	49	49
				51	49	49	49	49	49	49	49	51	49	49	49	49	49	49	49
				49	49	49	49	49	49	49	49	49	49	49	49	49	49	49	49
				51	49	49	49	49	49	51	51	51	49	49	49	49	49	49	49
				49	49	49	49	49	49	49	49	49	49	49	49	49	49	49	49
				51	49	49	49	49	49	51	51	49	49	49	49	49	49	49	49
				49	49	49	49	49	49	49	49	49	49	49	49	49	49	49	49
				51	49	49	49	51	49	49	49	51	51	49	51	49	49	49	49
				49	49	49	49	49	49	49	49	49	49	49	49	49	49	49	49
				51	49	49	49	49	49	49	51	49	49	49	49	49	49	49	49
				49	49	49	49	49	49	49	49	51	49	49	49	49	49	49	49
				51	49	49	49	49	49	51	51	49	49	49	49	49	49	49	49
				49	49	49	49	49	49	49	49	51	49	49	49	49	49	49	51
				51	49	49	49	49	51	51	51	51	51	49	49	49	49	49	51
				49	49	49	49	49	49	49	49	51	49	49	49	49	49	49	51
				51	49	49	49	49	49	51	51	49	49	49	49	49	49	49	51
				49	49	49	49	49	49	49	49	51	49	49	49	49	49	49	51
				51	49	51	51	51	51	51	51	49	49	49	49	49	49	49	51
				49	49	49	49	49	49	49	49	51	51	51	49	49	49	51	51
				51	49	51	51	51	51	51	51	49	49	49	49	49	49	49	51
				49	49	49	49	49	49	49	49	51	51	51	51	51	51	51	51
				51	51	51	51	51	51	51	51	51	51	51	49	49	49	49	51
				49	49	49	49	49	49	49	51	51	51	51	49	49	49	51	51
				51	51	51	51	51	51	51	51	51	51	51	51	51	51	51	51
				51	51	51	51	51	51	51	51	51	51	51	51	51	51	51	51
				51	51	51	51	51	51	51	52	51	51	51	51	51	51	49	51
				51	49	49	51	49	51	51	51	51	51	51	49	51	49	49	51
				51	51	51	51	51	51	51	51	51	51	51	49	51	49	49	51
				51	51	51	51	51	51	51	51	51	49	49	49	49	49	49	49
				52	51	51	51	51	51	51	52	51	51	51	51	51	51	51	52
				314 314 314>;

			PS_Config_Lmt_FW_CC_N = <
				22	21	21	21	21	22	22	22	22	22	22	22	21	21	21	22
				22	22	22	22	22	22	22	22	22	22	22	22	21	21	21	22
				22	22	22	22	22	22	22	22	22	22	22	22	22	22	22	22
				22	22	22	22	22	22	22	22	22	22	22	22	22	22	22	22
				22	22	22	22	22	22	22	22	22	22	22	22	22	22	22	22
				22	22	22	22	22	22	22	22	22	22	22	22	22	22	22	22
				22	22	22	22	22	22	22	22	22	22	22	22	22	22	22	22
				22	22	22	22	22	22	22	22	22	22	22	22	22	22	22	22
				22	22	22	22	22	22	22	22	22	22	22	22	22	22	22	22
				22	22	22	22	22	22	22	22	22	22	22	22	22	22	22	22
				22	22	22	22	22	22	22	22	22	22	22	22	22	22	22	22
				22	22	22	22	22	22	22	22	22	22	22	22	22	22	22	22
				22	22	22	22	22	22	22	22	22	22	22	22	22	22	22	22
				22	22	22	22	22	22	22	22	22	22	22	22	22	22	22	22
				22	22	22	22	22	22	22	22	22	22	22	22	22	22	22	22
				22	22	22	22	22	22	22	22	22	22	22	22	22	22	22	22
				22	22	22	22	22	22	22	22	22	22	22	22	22	22	22	22
				22	22	22	22	22	22	22	22	22	22	22	22	22	22	22	22
				22	22	22	22	22	22	22	22	22	22	22	22	22	22	22	22
				22	22	22	22	22	22	22	22	22	22	22	22	22	22	22	22
				22	22	22	22	22	22	22	22	22	22	22	22	22	22	22	22
				22	22	22	22	22	22	22	22	22	22	22	22	22	22	22	22
				22	22	22	22	22	22	22	22	22	22	22	22	22	22	22	22
				22	22	22	22	22	22	22	22	22	22	22	22	22	22	22	22
				22	22	22	22	22	22	22	22	22	22	22	22	22	22	22	22
				22	22	22	22	22	22	22	22	22	22	22	22	22	22	22	22
				22	22	22	22	22	22	22	22	22	22	22	22	22	22	22	22
				22	22	22	22	22	22	22	22	22	22	22	22	22	22	22	22
				22	22	22	22	22	22	22	22	22	22	22	22	22	22	22	22
				22	22	22	22	22	22	22	22	22	22	22	22	22	22	22	22
				22	22	22	22	22	22	22	22	22	22	22	22	22	22	22	22
				22	22	22	22	22	22	22	23	22	22	22	22	22	22	22	22
				22	22	22	22	22	22	22	22	22	22	22	22	22	22	22	22
				22	22	22	22	22	22	22	22	22	22	22	22	22	22	22	22
				22	22	22	22	22	22	22	22	22	22	22	22	22	22	22	22
				23	22	22	22	22	22	22	23	22	22	22	22	22	22	22	23
				0 0 0>;

			PS_Config_Lmt_FW_Diff_P = <
				50	50	50	50	50	50	50	50	50	50	50	50	50	50	50	50
				50	50	50	50	50	50	50	50	50	50	50	50	50	50	50	50
				50	50	50	50	50	50	50	50	50	50	50	50	50	50	50	50
				50	50	50	50	50	50	50	50	50	50	50	50	50	50	50	50
				50	50	50	50	50	50	50	50	50	50	50	50	50	50	50	50
				50	50	50	50	50	50	50	50	50	50	50	50	50	50	50	50
				50	50	50	50	50	50	50	50	50	50	50	50	50	50	50	50
				50	50	50	50	50	50	50	50	50	50	50	50	50	50	50	50
				50	50	50	50	50	50	50	50	50	50	50	50	50	50	50	50
				50	50	50	50	50	50	50	50	50	50	50	50	50	50	50	50
				50	50	50	50	50	50	50	50	50	50	50	50	50	50	50	50
				50	50	50	50	50	50	50	50	50	50	50	50	50	50	50	50
				50	50	50	50	50	50	50	50	50	50	50	50	50	50	50	50
				50	50	50	50	50	50	50	50	50	50	50	50	50	50	50	50
				50	50	50	50	50	50	50	50	50	50	50	50	50	50	50	50
				50	50	50	50	50	50	50	50	50	50	50	50	50	50	50	50
				50	50	50	50	50	50	50	50	50	50	50	50	50	50	50	50
				50	50	50	50	50	50	50	50	50	50	50	50	50	50	50	50
				50	50	50	50	50	50	50	50	50	50	50	50	50	50	50	50
				50	50	50	50	50	50	50	50	50	50	50	50	50	50	50	50
				50	50	50	50	50	50	50	50	50	50	50	50	50	50	50	50
				50	50	50	50	50	50	50	50	50	50	50	50	50	50	50	50
				50	50	50	50	50	50	50	50	50	50	50	50	50	50	50	50
				50	50	50	50	50	50	50	50	50	50	50	50	50	50	50	50
				50	50	50	50	50	50	50	50	50	50	50	50	50	50	50	50
				50	50	50	50	50	50	50	50	50	50	50	50	50	50	50	50
				50	50	50	50	50	50	50	50	50	50	50	50	50	50	50	50
				50	50	50	50	50	50	50	50	50	50	50	50	50	50	50	50
				50	50	50	50	50	50	50	50	50	50	50	50	50	50	50	50
				50	50	50	50	50	50	50	50	50	50	50	50	50	50	50	50
				50	50	50	50	50	50	50	50	50	50	50	50	50	50	50	50
				50	50	50	50	50	50	50	50	50	50	50	50	50	50	50	50
				50	50	50	50	50	50	50	50	50	50	50	50	50	50	50	50
				50	50	50	50	50	50	50	50	50	50	50	50	50	50	50	50
				50	50	50	50	50	50	50	50	50	50	50	50	50	50	50	50
				50	50	50	50	50	50	50	50	50	50	50	50	50	50	50	50
				75 75 75>;

			PS_Config_Lmt_FW_Diff_N = <
				(-50)	(-50)	(-50)	(-50)	(-50)	(-50)	(-50)	(-50)	(-50)	(-50)	(-50)	(-50)	(-50)	(-50)	(-50)	(-50)
				(-50)	(-50)	(-50)	(-50)	(-50)	(-50)	(-50)	(-50)	(-50)	(-50)	(-50)	(-50)	(-50)	(-50)	(-50)	(-50)
				(-50)	(-50)	(-50)	(-50)	(-50)	(-50)	(-50)	(-50)	(-50)	(-50)	(-50)	(-50)	(-50)	(-50)	(-50)	(-50)
				(-50)	(-50)	(-50)	(-50)	(-50)	(-50)	(-50)	(-50)	(-50)	(-50)	(-50)	(-50)	(-50)	(-50)	(-50)	(-50)
				(-50)	(-50)	(-50)	(-50)	(-50)	(-50)	(-50)	(-50)	(-50)	(-50)	(-50)	(-50)	(-50)	(-50)	(-50)	(-50)
				(-50)	(-50)	(-50)	(-50)	(-50)	(-50)	(-50)	(-50)	(-50)	(-50)	(-50)	(-50)	(-50)	(-50)	(-50)	(-50)
				(-50)	(-50)	(-50)	(-50)	(-50)	(-50)	(-50)	(-50)	(-50)	(-50)	(-50)	(-50)	(-50)	(-50)	(-50)	(-50)
				(-50)	(-50)	(-50)	(-50)	(-50)	(-50)	(-50)	(-50)	(-50)	(-50)	(-50)	(-50)	(-50)	(-50)	(-50)	(-50)
				(-50)	(-50)	(-50)	(-50)	(-50)	(-50)	(-50)	(-50)	(-50)	(-50)	(-50)	(-50)	(-50)	(-50)	(-50)	(-50)
				(-50)	(-50)	(-50)	(-50)	(-50)	(-50)	(-50)	(-50)	(-50)	(-50)	(-50)	(-50)	(-50)	(-50)	(-50)	(-50)
				(-50)	(-50)	(-50)	(-50)	(-50)	(-50)	(-50)	(-50)	(-50)	(-50)	(-50)	(-50)	(-50)	(-50)	(-50)	(-50)
				(-50)	(-50)	(-50)	(-50)	(-50)	(-50)	(-50)	(-50)	(-50)	(-50)	(-50)	(-50)	(-50)	(-50)	(-50)	(-50)
				(-50)	(-50)	(-50)	(-50)	(-50)	(-50)	(-50)	(-50)	(-50)	(-50)	(-50)	(-50)	(-50)	(-50)	(-50)	(-50)
				(-50)	(-50)	(-50)	(-50)	(-50)	(-50)	(-50)	(-50)	(-50)	(-50)	(-50)	(-50)	(-50)	(-50)	(-50)	(-50)
				(-50)	(-50)	(-50)	(-50)	(-50)	(-50)	(-50)	(-50)	(-50)	(-50)	(-50)	(-50)	(-50)	(-50)	(-50)	(-50)
				(-50)	(-50)	(-50)	(-50)	(-50)	(-50)	(-50)	(-50)	(-50)	(-50)	(-50)	(-50)	(-50)	(-50)	(-50)	(-50)
				(-50)	(-50)	(-50)	(-50)	(-50)	(-50)	(-50)	(-50)	(-50)	(-50)	(-50)	(-50)	(-50)	(-50)	(-50)	(-50)
				(-50)	(-50)	(-50)	(-50)	(-50)	(-50)	(-50)	(-50)	(-50)	(-50)	(-50)	(-50)	(-50)	(-50)	(-50)	(-50)
				(-50)	(-50)	(-50)	(-50)	(-50)	(-50)	(-50)	(-50)	(-50)	(-50)	(-50)	(-50)	(-50)	(-50)	(-50)	(-50)
				(-50)	(-50)	(-50)	(-50)	(-50)	(-50)	(-50)	(-50)	(-50)	(-50)	(-50)	(-50)	(-50)	(-50)	(-50)	(-50)
				(-50)	(-50)	(-50)	(-50)	(-50)	(-50)	(-50)	(-50)	(-50)	(-50)	(-50)	(-50)	(-50)	(-50)	(-50)	(-50)
				(-50)	(-50)	(-50)	(-50)	(-50)	(-50)	(-50)	(-50)	(-50)	(-50)	(-50)	(-50)	(-50)	(-50)	(-50)	(-50)
				(-50)	(-50)	(-50)	(-50)	(-50)	(-50)	(-50)	(-50)	(-50)	(-50)	(-50)	(-50)	(-50)	(-50)	(-50)	(-50)
				(-50)	(-50)	(-50)	(-50)	(-50)	(-50)	(-50)	(-50)	(-50)	(-50)	(-50)	(-50)	(-50)	(-50)	(-50)	(-50)
				(-50)	(-50)	(-50)	(-50)	(-50)	(-50)	(-50)	(-50)	(-50)	(-50)	(-50)	(-50)	(-50)	(-50)	(-50)	(-50)
				(-50)	(-50)	(-50)	(-50)	(-50)	(-50)	(-50)	(-50)	(-50)	(-50)	(-50)	(-50)	(-50)	(-50)	(-50)	(-50)
				(-50)	(-50)	(-50)	(-50)	(-50)	(-50)	(-50)	(-50)	(-50)	(-50)	(-50)	(-50)	(-50)	(-50)	(-50)	(-50)
				(-50)	(-50)	(-50)	(-50)	(-50)	(-50)	(-50)	(-50)	(-50)	(-50)	(-50)	(-50)	(-50)	(-50)	(-50)	(-50)
				(-50)	(-50)	(-50)	(-50)	(-50)	(-50)	(-50)	(-50)	(-50)	(-50)	(-50)	(-50)	(-50)	(-50)	(-50)	(-50)
				(-50)	(-50)	(-50)	(-50)	(-50)	(-50)	(-50)	(-50)	(-50)	(-50)	(-50)	(-50)	(-50)	(-50)	(-50)	(-50)
				(-50)	(-50)	(-50)	(-50)	(-50)	(-50)	(-50)	(-50)	(-50)	(-50)	(-50)	(-50)	(-50)	(-50)	(-50)	(-50)
				(-50)	(-50)	(-50)	(-50)	(-50)	(-50)	(-50)	(-50)	(-50)	(-50)	(-50)	(-50)	(-50)	(-50)	(-50)	(-50)
				(-50)	(-50)	(-50)	(-50)	(-50)	(-50)	(-50)	(-50)	(-50)	(-50)	(-50)	(-50)	(-50)	(-50)	(-50)	(-50)
				(-50)	(-50)	(-50)	(-50)	(-50)	(-50)	(-50)	(-50)	(-50)	(-50)	(-50)	(-50)	(-50)	(-50)	(-50)	(-50)
				(-50)	(-50)	(-50)	(-50)	(-50)	(-50)	(-50)	(-50)	(-50)	(-50)	(-50)	(-50)	(-50)	(-50)	(-50)	(-50)
				(-50)	(-50)	(-50)	(-50)	(-50)	(-50)	(-50)	(-50)	(-50)	(-50)	(-50)	(-50)	(-50)	(-50)	(-50)	(-50)
				(-75) (-75) (-75)>;

			PS_Config_Lmt_PenTipX_FW_Raw_P = <
				570 570 570 570 570 570 570 570 570 570 570 570 570 570 570 570 570 570 570 570 570 570 570 570 570 570 570 570 570 570 570 570
				570 570 570 570 570 570 570 570 570 570 570 570 570 570 570 570 570 570 570 570 570 570 570 570 570 570 570 570 570 570 570 570
				570 570 570 570 570 570 570 570 570 570 570 570 570 570 570 570 570 570 570 570 570 570 570 570 570 570 570 570 570 570 570 570
				570 570 570 570 570 570 570 570 570 570 570 570 570 570 570 570 570 570 570 570 570 570 570 570 570 570 570 570 570 570 570 570
				570 570 570 570 570 570 570 570 570 570 570 570 570 570 570 570 570 570 570 570 570 570 570 570 570 570 570 570 570 570 570 570
				570 570 570 570 570 570 570 570 570 570 570 570 570 570 570 570 570 570 570 570 570 570 570 570 570 570 570 570 570 570 570 570>;

			PS_Config_Lmt_PenTipX_FW_Raw_N = <
				(-570) (-570) (-570) (-570) (-570) (-570) (-570) (-570) (-570) (-570) (-570) (-570) (-570) (-570) (-570) (-570) (-570) (-570) (-570) (-570) (-570) (-570) (-570) (-570) (-570) (-570) (-570) (-570) (-570) (-570) (-570) (-570)
				(-570) (-570) (-570) (-570) (-570) (-570) (-570) (-570) (-570) (-570) (-570) (-570) (-570) (-570) (-570) (-570) (-570) (-570) (-570) (-570) (-570) (-570) (-570) (-570) (-570) (-570) (-570) (-570) (-570) (-570) (-570) (-570)
				(-570) (-570) (-570) (-570) (-570) (-570) (-570) (-570) (-570) (-570) (-570) (-570) (-570) (-570) (-570) (-570) (-570) (-570) (-570) (-570) (-570) (-570) (-570) (-570) (-570) (-570) (-570) (-570) (-570) (-570) (-570) (-570)
				(-570) (-570) (-570) (-570) (-570) (-570) (-570) (-570) (-570) (-570) (-570) (-570) (-570) (-570) (-570) (-570) (-570) (-570) (-570) (-570) (-570) (-570) (-570) (-570) (-570) (-570) (-570) (-570) (-570) (-570) (-570) (-570)
				(-570) (-570) (-570) (-570) (-570) (-570) (-570) (-570) (-570) (-570) (-570) (-570) (-570) (-570) (-570) (-570) (-570) (-570) (-570) (-570) (-570) (-570) (-570) (-570) (-570) (-570) (-570) (-570) (-570) (-570) (-570) (-570)
				(-570) (-570) (-570) (-570) (-570) (-570) (-570) (-570) (-570) (-570) (-570) (-570) (-570) (-570) (-570) (-570) (-570) (-570) (-570) (-570) (-570) (-570) (-570) (-570) (-570) (-570) (-570) (-570) (-570) (-570) (-570) (-570)>;

			PS_Config_Lmt_PenTipY_FW_Raw_P = <
				570 570 570 570
				570 570 570 570
				570 570 570 570
				570 570 570 570
				570 570 570 570
				570 570 570 570
				570 570 570 570
				570 570 570 570
				570 570 570 570
				570 570 570 570
				570 570 570 570
				570 570 570 570
				570 570 570 570
				570 570 570 570
				570 570 570 570
				570 570 570 570
				570 570 570 570
				570 570 570 570
				570 570 570 570
				570 570 570 570
				570 570 570 570
				570 570 570 570
				570 570 570 570
				570 570 570 570
				570 570 570 570
				570 570 570 570
				570 570 570 570
				570 570 570 570
				570 570 570 570
				570 570 570 570
				570 570 570 570
				570 570 570 570
				570 570 570 570
				570 570 570 570
				570 570 570 570
				570 570 570 570
				570 570 570 570
				570 570 570 570
				570 570 570 570
				570 570 570 570
				570 570 570 570
				570 570 570 570
				570 570 570 570
				570 570 570 570
				570 570 570 570
				570 570 570 570
				570 570 570 570
				570 570 570 570
				570 570 570 570
				570 570 570 570>;

			PS_Config_Lmt_PenTipY_FW_Raw_N = <
				(-570) (-570) (-570) (-570)
				(-570) (-570) (-570) (-570)
				(-570) (-570) (-570) (-570)
				(-570) (-570) (-570) (-570)
				(-570) (-570) (-570) (-570)
				(-570) (-570) (-570) (-570)
				(-570) (-570) (-570) (-570)
				(-570) (-570) (-570) (-570)
				(-570) (-570) (-570) (-570)
				(-570) (-570) (-570) (-570)
				(-570) (-570) (-570) (-570)
				(-570) (-570) (-570) (-570)
				(-570) (-570) (-570) (-570)
				(-570) (-570) (-570) (-570)
				(-570) (-570) (-570) (-570)
				(-570) (-570) (-570) (-570)
				(-570) (-570) (-570) (-570)
				(-570) (-570) (-570) (-570)
				(-570) (-570) (-570) (-570)
				(-570) (-570) (-570) (-570)
				(-570) (-570) (-570) (-570)
				(-570) (-570) (-570) (-570)
				(-570) (-570) (-570) (-570)
				(-570) (-570) (-570) (-570)
				(-570) (-570) (-570) (-570)
				(-570) (-570) (-570) (-570)
				(-570) (-570) (-570) (-570)
				(-570) (-570) (-570) (-570)
				(-570) (-570) (-570) (-570)
				(-570) (-570) (-570) (-570)
				(-570) (-570) (-570) (-570)
				(-570) (-570) (-570) (-570)
				(-570) (-570) (-570) (-570)
				(-570) (-570) (-570) (-570)
				(-570) (-570) (-570) (-570)
				(-570) (-570) (-570) (-570)
				(-570) (-570) (-570) (-570)
				(-570) (-570) (-570) (-570)
				(-570) (-570) (-570) (-570)
				(-570) (-570) (-570) (-570)
				(-570) (-570) (-570) (-570)
				(-570) (-570) (-570) (-570)
				(-570) (-570) (-570) (-570)
				(-570) (-570) (-570) (-570)
				(-570) (-570) (-570) (-570)
				(-570) (-570) (-570) (-570)
				(-570) (-570) (-570) (-570)
				(-570) (-570) (-570) (-570)
				(-570) (-570) (-570) (-570)
				(-570) (-570) (-570) (-570)>;

			PS_Config_Lmt_PenRingX_FW_Raw_P = <
				570 570 570 570 570 570 570 570 570 570 570 570 570 570 570 570 570 570 570 570 570 570 570 570 570 570 570 570 570 570 570 570
				570 570 570 570 570 570 570 570 570 570 570 570 570 570 570 570 570 570 570 570 570 570 570 570 570 570 570 570 570 570 570 570
				570 570 570 570 570 570 570 570 570 570 570 570 570 570 570 570 570 570 570 570 570 570 570 570 570 570 570 570 570 570 570 570
				570 570 570 570 570 570 570 570 570 570 570 570 570 570 570 570 570 570 570 570 570 570 570 570 570 570 570 570 570 570 570 570
				570 570 570 570 570 570 570 570 570 570 570 570 570 570 570 570 570 570 570 570 570 570 570 570 570 570 570 570 570 570 570 570
				570 570 570 570 570 570 570 570 570 570 570 570 570 570 570 570 570 570 570 570 570 570 570 570 570 570 570 570 570 570 570 570>;

			PS_Config_Lmt_PenRingX_FW_Raw_N = <
				(-570) (-570) (-570) (-570) (-570) (-570) (-570) (-570) (-570) (-570) (-570) (-570) (-570) (-570) (-570) (-570) (-570) (-570) (-570) (-570) (-570) (-570) (-570) (-570) (-570) (-570) (-570) (-570) (-570) (-570) (-570) (-570)
				(-570) (-570) (-570) (-570) (-570) (-570) (-570) (-570) (-570) (-570) (-570) (-570) (-570) (-570) (-570) (-570) (-570) (-570) (-570) (-570) (-570) (-570) (-570) (-570) (-570) (-570) (-570) (-570) (-570) (-570) (-570) (-570)
				(-570) (-570) (-570) (-570) (-570) (-570) (-570) (-570) (-570) (-570) (-570) (-570) (-570) (-570) (-570) (-570) (-570) (-570) (-570) (-570) (-570) (-570) (-570) (-570) (-570) (-570) (-570) (-570) (-570) (-570) (-570) (-570)
				(-570) (-570) (-570) (-570) (-570) (-570) (-570) (-570) (-570) (-570) (-570) (-570) (-570) (-570) (-570) (-570) (-570) (-570) (-570) (-570) (-570) (-570) (-570) (-570) (-570) (-570) (-570) (-570) (-570) (-570) (-570) (-570)
				(-570) (-570) (-570) (-570) (-570) (-570) (-570) (-570) (-570) (-570) (-570) (-570) (-570) (-570) (-570) (-570) (-570) (-570) (-570) (-570) (-570) (-570) (-570) (-570) (-570) (-570) (-570) (-570) (-570) (-570) (-570) (-570)
				(-570) (-570) (-570) (-570) (-570) (-570) (-570) (-570) (-570) (-570) (-570) (-570) (-570) (-570) (-570) (-570) (-570) (-570) (-570) (-570) (-570) (-570) (-570) (-570) (-570) (-570) (-570) (-570) (-570) (-570) (-570) (-570)>;

			PS_Config_Lmt_PenRingY_FW_Raw_P = <
				570 570 570 570
				570 570 570 570
				570 570 570 570
				570 570 570 570
				570 570 570 570
				570 570 570 570
				570 570 570 570
				570 570 570 570
				570 570 570 570
				570 570 570 570
				570 570 570 570
				570 570 570 570
				570 570 570 570
				570 570 570 570
				570 570 570 570
				570 570 570 570
				570 570 570 570
				570 570 570 570
				570 570 570 570
				570 570 570 570
				570 570 570 570
				570 570 570 570
				570 570 570 570
				570 570 570 570
				570 570 570 570
				570 570 570 570
				570 570 570 570
				570 570 570 570
				570 570 570 570
				570 570 570 570
				570 570 570 570
				570 570 570 570
				570 570 570 570
				570 570 570 570
				570 570 570 570
				570 570 570 570
				570 570 570 570
				570 570 570 570
				570 570 570 570
				570 570 570 570
				570 570 570 570
				570 570 570 570
				570 570 570 570
				570 570 570 570
				570 570 570 570
				570 570 570 570
				570 570 570 570
				570 570 570 570
				570 570 570 570
				570 570 570 570>;

			PS_Config_Lmt_PenRingY_FW_Raw_N = <
				(-570) (-570) (-570) (-570)
				(-570) (-570) (-570) (-570)
				(-570) (-570) (-570) (-570)
				(-570) (-570) (-570) (-570)
				(-570) (-570) (-570) (-570)
				(-570) (-570) (-570) (-570)
				(-570) (-570) (-570) (-570)
				(-570) (-570) (-570) (-570)
				(-570) (-570) (-570) (-570)
				(-570) (-570) (-570) (-570)
				(-570) (-570) (-570) (-570)
				(-570) (-570) (-570) (-570)
				(-570) (-570) (-570) (-570)
				(-570) (-570) (-570) (-570)
				(-570) (-570) (-570) (-570)
				(-570) (-570) (-570) (-570)
				(-570) (-570) (-570) (-570)
				(-570) (-570) (-570) (-570)
				(-570) (-570) (-570) (-570)
				(-570) (-570) (-570) (-570)
				(-570) (-570) (-570) (-570)
				(-570) (-570) (-570) (-570)
				(-570) (-570) (-570) (-570)
				(-570) (-570) (-570) (-570)
				(-570) (-570) (-570) (-570)
				(-570) (-570) (-570) (-570)
				(-570) (-570) (-570) (-570)
				(-570) (-570) (-570) (-570)
				(-570) (-570) (-570) (-570)
				(-570) (-570) (-570) (-570)
				(-570) (-570) (-570) (-570)
				(-570) (-570) (-570) (-570)
				(-570) (-570) (-570) (-570)
				(-570) (-570) (-570) (-570)
				(-570) (-570) (-570) (-570)
				(-570) (-570) (-570) (-570)
				(-570) (-570) (-570) (-570)
				(-570) (-570) (-570) (-570)
				(-570) (-570) (-570) (-570)
				(-570) (-570) (-570) (-570)
				(-570) (-570) (-570) (-570)
				(-570) (-570) (-570) (-570)
				(-570) (-570) (-570) (-570)
				(-570) (-570) (-570) (-570)
				(-570) (-570) (-570) (-570)
				(-570) (-570) (-570) (-570)
				(-570) (-570) (-570) (-570)
				(-570) (-570) (-570) (-570)
				(-570) (-570) (-570) (-570)
				(-570) (-570) (-570) (-570)>;

			PS_Config_Lmt_PenTipX_FW_Diff_P = <
				870 870 870 870 870 870 870 870 870 870 870 870 870 870 870 870 870 870 870 870 870 870 870 870 870 870 870 870 870 870 870 870
				870 870 870 870 870 870 870 870 870 870 870 870 870 870 870 870 870 870 870 870 870 870 870 870 870 870 870 870 870 870 870 870
				870 870 870 870 870 870 870 870 870 870 870 870 870 870 870 870 870 870 870 870 870 870 870 870 870 870 870 870 870 870 870 870
				870 870 870 870 870 870 870 870 870 870 870 870 870 870 870 870 870 870 870 870 870 870 870 870 870 870 870 870 870 870 870 870
				870 870 870 870 870 870 870 870 870 870 870 870 870 870 870 870 870 870 870 870 870 870 870 870 870 870 870 870 870 870 870 870
				870 870 870 870 870 870 870 870 870 870 870 870 870 870 870 870 870 870 870 870 870 870 870 870 870 870 870 870 870 870 870 870>;

			PS_Config_Lmt_PenTipX_FW_Diff_N = <
				(-870) (-870) (-870) (-870) (-870) (-870) (-870) (-870) (-870) (-870) (-870) (-870) (-870) (-870) (-870) (-870) (-870) (-870) (-870) (-870) (-870) (-870) (-870) (-870) (-870) (-870) (-870) (-870) (-870) (-870) (-870) (-870)
				(-870) (-870) (-870) (-870) (-870) (-870) (-870) (-870) (-870) (-870) (-870) (-870) (-870) (-870) (-870) (-870) (-870) (-870) (-870) (-870) (-870) (-870) (-870) (-870) (-870) (-870) (-870) (-870) (-870) (-870) (-870) (-870)
				(-870) (-870) (-870) (-870) (-870) (-870) (-870) (-870) (-870) (-870) (-870) (-870) (-870) (-870) (-870) (-870) (-870) (-870) (-870) (-870) (-870) (-870) (-870) (-870) (-870) (-870) (-870) (-870) (-870) (-870) (-870) (-870)
				(-870) (-870) (-870) (-870) (-870) (-870) (-870) (-870) (-870) (-870) (-870) (-870) (-870) (-870) (-870) (-870) (-870) (-870) (-870) (-870) (-870) (-870) (-870) (-870) (-870) (-870) (-870) (-870) (-870) (-870) (-870) (-870)
				(-870) (-870) (-870) (-870) (-870) (-870) (-870) (-870) (-870) (-870) (-870) (-870) (-870) (-870) (-870) (-870) (-870) (-870) (-870) (-870) (-870) (-870) (-870) (-870) (-870) (-870) (-870) (-870) (-870) (-870) (-870) (-870)
				(-870) (-870) (-870) (-870) (-870) (-870) (-870) (-870) (-870) (-870) (-870) (-870) (-870) (-870) (-870) (-870) (-870) (-870) (-870) (-870) (-870) (-870) (-870) (-870) (-870) (-870) (-870) (-870) (-870) (-870) (-870) (-870)>;

			PS_Config_Lmt_PenTipY_FW_Diff_P = <
				870 870 870 870
				870 870 870 870
				870 870 870 870
				870 870 870 870
				870 870 870 870
				870 870 870 870
				870 870 870 870
				870 870 870 870
				870 870 870 870
				870 870 870 870
				870 870 870 870
				870 870 870 870
				870 870 870 870
				870 870 870 870
				870 870 870 870
				870 870 870 870
				870 870 870 870
				870 870 870 870
				870 870 870 870
				870 870 870 870
				870 870 870 870
				870 870 870 870
				870 870 870 870
				870 870 870 870
				870 870 870 870
				870 870 870 870
				870 870 870 870
				870 870 870 870
				870 870 870 870
				870 870 870 870
				870 870 870 870
				870 870 870 870
				870 870 870 870
				870 870 870 870
				870 870 870 870
				870 870 870 870
				870 870 870 870
				870 870 870 870
				870 870 870 870
				870 870 870 870
				870 870 870 870
				870 870 870 870
				870 870 870 870
				870 870 870 870
				870 870 870 870
				870 870 870 870
				870 870 870 870
				870 870 870 870
				870 870 870 870
				870 870 870 870>;

			PS_Config_Lmt_PenTipY_FW_Diff_N = <
				(-870) (-870) (-870) (-870)
				(-870) (-870) (-870) (-870)
				(-870) (-870) (-870) (-870)
				(-870) (-870) (-870) (-870)
				(-870) (-870) (-870) (-870)
				(-870) (-870) (-870) (-870)
				(-870) (-870) (-870) (-870)
				(-870) (-870) (-870) (-870)
				(-870) (-870) (-870) (-870)
				(-870) (-870) (-870) (-870)
				(-870) (-870) (-870) (-870)
				(-870) (-870) (-870) (-870)
				(-870) (-870) (-870) (-870)
				(-870) (-870) (-870) (-870)
				(-870) (-870) (-870) (-870)
				(-870) (-870) (-870) (-870)
				(-870) (-870) (-870) (-870)
				(-870) (-870) (-870) (-870)
				(-870) (-870) (-870) (-870)
				(-870) (-870) (-870) (-870)
				(-870) (-870) (-870) (-870)
				(-870) (-870) (-870) (-870)
				(-870) (-870) (-870) (-870)
				(-870) (-870) (-870) (-870)
				(-870) (-870) (-870) (-870)
				(-870) (-870) (-870) (-870)
				(-870) (-870) (-870) (-870)
				(-870) (-870) (-870) (-870)
				(-870) (-870) (-870) (-870)
				(-870) (-870) (-870) (-870)
				(-870) (-870) (-870) (-870)
				(-870) (-870) (-870) (-870)
				(-870) (-870) (-870) (-870)
				(-870) (-870) (-870) (-870)
				(-870) (-870) (-870) (-870)
				(-870) (-870) (-870) (-870)
				(-870) (-870) (-870) (-870)
				(-870) (-870) (-870) (-870)
				(-870) (-870) (-870) (-870)
				(-870) (-870) (-870) (-870)
				(-870) (-870) (-870) (-870)
				(-870) (-870) (-870) (-870)
				(-870) (-870) (-870) (-870)
				(-870) (-870) (-870) (-870)
				(-870) (-870) (-870) (-870)
				(-870) (-870) (-870) (-870)
				(-870) (-870) (-870) (-870)
				(-870) (-870) (-870) (-870)
				(-870) (-870) (-870) (-870)
				(-870) (-870) (-870) (-870)>;

			PS_Config_Lmt_PenRingX_FW_Diff_P = <
				870 870 870 870 870 870 870 870 870 870 870 870 870 870 870 870 870 870 870 870 870 870 870 870 870 870 870 870 870 870 870 870
				870 870 870 870 870 870 870 870 870 870 870 870 870 870 870 870 870 870 870 870 870 870 870 870 870 870 870 870 870 870 870 870
				870 870 870 870 870 870 870 870 870 870 870 870 870 870 870 870 870 870 870 870 870 870 870 870 870 870 870 870 870 870 870 870
				870 870 870 870 870 870 870 870 870 870 870 870 870 870 870 870 870 870 870 870 870 870 870 870 870 870 870 870 870 870 870 870
				870 870 870 870 870 870 870 870 870 870 870 870 870 870 870 870 870 870 870 870 870 870 870 870 870 870 870 870 870 870 870 870
				870 870 870 870 870 870 870 870 870 870 870 870 870 870 870 870 870 870 870 870 870 870 870 870 870 870 870 870 870 870 870 870>;

			PS_Config_Lmt_PenRingX_FW_Diff_N = <
				(-870) (-870) (-870) (-870) (-870) (-870) (-870) (-870) (-870) (-870) (-870) (-870) (-870) (-870) (-870) (-870) (-870) (-870) (-870) (-870) (-870) (-870) (-870) (-870) (-870) (-870) (-870) (-870) (-870) (-870) (-870) (-870)
				(-870) (-870) (-870) (-870) (-870) (-870) (-870) (-870) (-870) (-870) (-870) (-870) (-870) (-870) (-870) (-870) (-870) (-870) (-870) (-870) (-870) (-870) (-870) (-870) (-870) (-870) (-870) (-870) (-870) (-870) (-870) (-870)
				(-870) (-870) (-870) (-870) (-870) (-870) (-870) (-870) (-870) (-870) (-870) (-870) (-870) (-870) (-870) (-870) (-870) (-870) (-870) (-870) (-870) (-870) (-870) (-870) (-870) (-870) (-870) (-870) (-870) (-870) (-870) (-870)
				(-870) (-870) (-870) (-870) (-870) (-870) (-870) (-870) (-870) (-870) (-870) (-870) (-870) (-870) (-870) (-870) (-870) (-870) (-870) (-870) (-870) (-870) (-870) (-870) (-870) (-870) (-870) (-870) (-870) (-870) (-870) (-870)
				(-870) (-870) (-870) (-870) (-870) (-870) (-870) (-870) (-870) (-870) (-870) (-870) (-870) (-870) (-870) (-870) (-870) (-870) (-870) (-870) (-870) (-870) (-870) (-870) (-870) (-870) (-870) (-870) (-870) (-870) (-870) (-870)
				(-870) (-870) (-870) (-870) (-870) (-870) (-870) (-870) (-870) (-870) (-870) (-870) (-870) (-870) (-870) (-870) (-870) (-870) (-870) (-870) (-870) (-870) (-870) (-870) (-870) (-870) (-870) (-870) (-870) (-870) (-870) (-870)>;

			PS_Config_Lmt_PenRingY_FW_Diff_P = <
				870 870 870 870
				870 870 870 870
				870 870 870 870
				870 870 870 870
				870 870 870 870
				870 870 870 870
				870 870 870 870
				870 870 870 870
				870 870 870 870
				870 870 870 870
				870 870 870 870
				870 870 870 870
				870 870 870 870
				870 870 870 870
				870 870 870 870
				870 870 870 870
				870 870 870 870
				870 870 870 870
				870 870 870 870
				870 870 870 870
				870 870 870 870
				870 870 870 870
				870 870 870 870
				870 870 870 870
				870 870 870 870
				870 870 870 870
				870 870 870 870
				870 870 870 870
				870 870 870 870
				870 870 870 870
				870 870 870 870
				870 870 870 870
				870 870 870 870
				870 870 870 870
				870 870 870 870
				870 870 870 870
				870 870 870 870
				870 870 870 870
				870 870 870 870
				870 870 870 870
				870 870 870 870
				870 870 870 870
				870 870 870 870
				870 870 870 870
				870 870 870 870
				870 870 870 870
				870 870 870 870
				870 870 870 870
				870 870 870 870
				870 870 870 870>;

			PS_Config_Lmt_PenRingY_FW_Diff_N = <
				(-870) (-870) (-870) (-870)
				(-870) (-870) (-870) (-870)
				(-870) (-870) (-870) (-870)
				(-870) (-870) (-870) (-870)
				(-870) (-870) (-870) (-870)
				(-870) (-870) (-870) (-870)
				(-870) (-870) (-870) (-870)
				(-870) (-870) (-870) (-870)
				(-870) (-870) (-870) (-870)
				(-870) (-870) (-870) (-870)
				(-870) (-870) (-870) (-870)
				(-870) (-870) (-870) (-870)
				(-870) (-870) (-870) (-870)
				(-870) (-870) (-870) (-870)
				(-870) (-870) (-870) (-870)
				(-870) (-870) (-870) (-870)
				(-870) (-870) (-870) (-870)
				(-870) (-870) (-870) (-870)
				(-870) (-870) (-870) (-870)
				(-870) (-870) (-870) (-870)
				(-870) (-870) (-870) (-870)
				(-870) (-870) (-870) (-870)
				(-870) (-870) (-870) (-870)
				(-870) (-870) (-870) (-870)
				(-870) (-870) (-870) (-870)
				(-870) (-870) (-870) (-870)
				(-870) (-870) (-870) (-870)
				(-870) (-870) (-870) (-870)
				(-870) (-870) (-870) (-870)
				(-870) (-870) (-870) (-870)
				(-870) (-870) (-870) (-870)
				(-870) (-870) (-870) (-870)
				(-870) (-870) (-870) (-870)
				(-870) (-870) (-870) (-870)
				(-870) (-870) (-870) (-870)
				(-870) (-870) (-870) (-870)
				(-870) (-870) (-870) (-870)
				(-870) (-870) (-870) (-870)
				(-870) (-870) (-870) (-870)
				(-870) (-870) (-870) (-870)
				(-870) (-870) (-870) (-870)
				(-870) (-870) (-870) (-870)
				(-870) (-870) (-870) (-870)
				(-870) (-870) (-870) (-870)
				(-870) (-870) (-870) (-870)
				(-870) (-870) (-870) (-870)
				(-870) (-870) (-870) (-870)
				(-870) (-870) (-870) (-870)
				(-870) (-870) (-870) (-870)
				(-870) (-870) (-870) (-870)>;

			PS_Config_Diff_Test_Frame = <50>;
		};
	};
};

/* Huaqin modify for HQ-152284 by jiangyue at 2021/09/17 end */

/* TOUCH end */
